[part 1 of 2: package /ComponentTypes]
AUTOSAR XML (schema 00046)
package /ComponentTypes
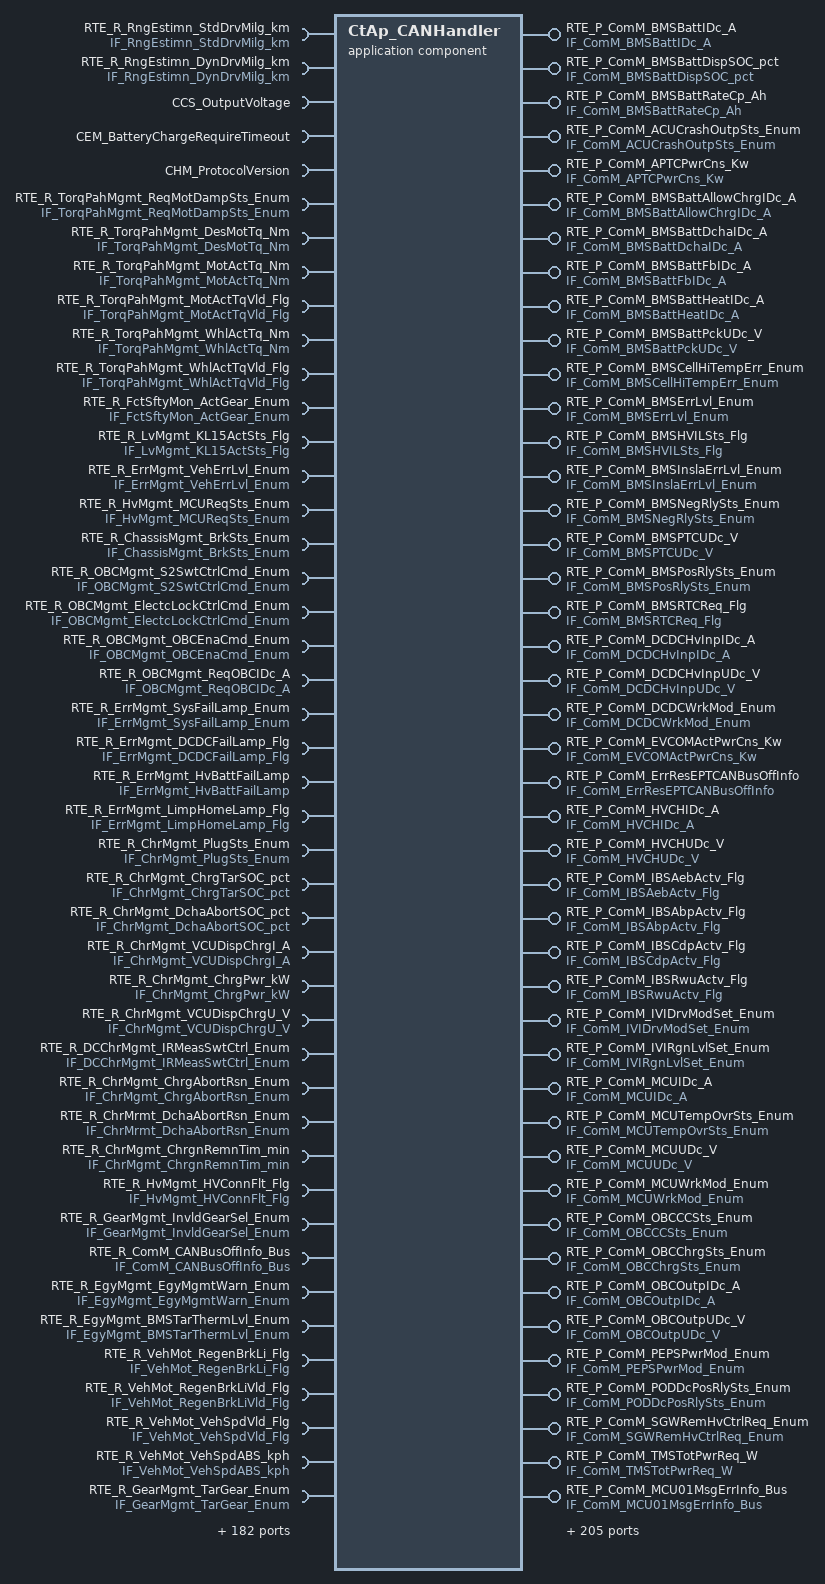
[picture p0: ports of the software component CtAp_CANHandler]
  application sw component type CtAp_CANHandler
    provide port RTE_P_ComM_BMSBattIDc_A: nonqueued-sender-com-spec{data-element=tec_ComM_BMSBattIDc_A, init-value=0}, provided-interface=IF_ComM_BMSBattIDc_A
    provide port RTE_P_ComM_BMSBattDispSOC_pct: nonqueued-sender-com-spec{data-element=tec_ComM_BMSBattDispSOC_pct, init-value=0}, provided-interface=IF_ComM_BMSBattDispSOC_pct
    provide port RTE_P_ComM_BMSBattRateCp_Ah: nonqueued-sender-com-spec{data-element=tec_ComM_BMSBattRateCp_Ah, init-value=0}, provided-interface=IF_ComM_BMSBattRateCp_Ah
    5 x require port:
      RTE_R_RngEstimn_StdDrvMilg_km: nonqueued-receiver-com-spec{data-element=tec_RngEstimn_StdDrvMilg_km, filter=data-filter-type=ALWAYS, init-value=0}, required-interface=IF_RngEstimn_StdDrvMilg_km
      RTE_R_RngEstimn_DynDrvMilg_km: nonqueued-receiver-com-spec{data-element=tec_RngEstimn_DynDrvMilg_km, filter=data-filter-type=ALWAYS, init-value=0}, required-interface=IF_RngEstimn_DynDrvMilg_km
      CCS_OutputVoltage: nonqueued-receiver-com-spec{data-element=CCS_OutputVoltage, init-value=0}, required-interface=CCS_OutputVoltage
      CEM_BatteryChargeRequireTimeout: nonqueued-receiver-com-spec{data-element=CEM_BatteryChargeRequireTimeout, init-value=0}, required-interface=CEM_BatteryChargeRequireTimeout
      CHM_ProtocolVersion: nonqueued-receiver-com-spec{data-element=CHM_ProtocolVersion, init-value=0}, required-interface=CHM_ProtocolVersion
    46 x provide port:
      RTE_P_ComM_ACUCrashOutpSts_Enum: nonqueued-sender-com-spec{data-element=tec_ComM_ACUCrashOutpSts_Enum, init-value=0}, provided-interface=IF_ComM_ACUCrashOutpSts_Enum
      RTE_P_ComM_APTCPwrCns_Kw: nonqueued-sender-com-spec{data-element=tec_ComM_APTCPwrCns_Kw, init-value=0}, provided-interface=IF_ComM_APTCPwrCns_Kw
      RTE_P_ComM_BMSBattAllowChrgIDc_A: nonqueued-sender-com-spec{data-element=tec_ComM_BMSBattAllowChrgIDc_A, init-value=0}, provided-interface=IF_ComM_BMSBattAllowChrgIDc_A
      RTE_P_ComM_BMSBattDchaIDc_A: nonqueued-sender-com-spec{data-element=tec_ComM_BMSBattDchaIDc_A, init-value=0}, provided-interface=IF_ComM_BMSBattDchaIDc_A
      RTE_P_ComM_BMSBattFbIDc_A: nonqueued-sender-com-spec{data-element=tec_ComM_BMSBattFbIDc_A, init-value=0}, provided-interface=IF_ComM_BMSBattFbIDc_A
      RTE_P_ComM_BMSBattHeatIDc_A: nonqueued-sender-com-spec{data-element=tec_ComM_BMSBattHeatIDc_A, init-value=0}, provided-interface=IF_ComM_BMSBattHeatIDc_A
      RTE_P_ComM_BMSBattPckUDc_V: nonqueued-sender-com-spec{data-element=tec_ComM_BMSBattPckUDc_V, init-value=0}, provided-interface=IF_ComM_BMSBattPckUDc_V
      RTE_P_ComM_BMSCellHiTempErr_Enum: nonqueued-sender-com-spec{data-element=tec_ComM_BMSCellHiTempErr_Enum, init-value=0}, provided-interface=IF_ComM_BMSCellHiTempErr_Enum
      RTE_P_ComM_BMSErrLvl_Enum: nonqueued-sender-com-spec{data-element=tec_ComM_BMSErrLvl_Enum, init-value=0}, provided-interface=IF_ComM_BMSErrLvl_Enum
      RTE_P_ComM_BMSHVILSts_Flg: nonqueued-sender-com-spec{data-element=tec_ComM_BMSHVILSts_Flg, init-value=0}, provided-interface=IF_ComM_BMSHVILSts_Flg
      RTE_P_ComM_BMSInslaErrLvl_Enum: nonqueued-sender-com-spec{data-element=tec_ComM_BMSInslaErrLvl_Enum, init-value=0}, provided-interface=IF_ComM_BMSInslaErrLvl_Enum
      RTE_P_ComM_BMSNegRlySts_Enum: nonqueued-sender-com-spec{data-element=tec_ComM_BMSNegRlySts_Enum, init-value=0}, provided-interface=IF_ComM_BMSNegRlySts_Enum
      RTE_P_ComM_BMSPTCUDc_V: nonqueued-sender-com-spec{data-element=tec_ComM_BMSPTCUDc_V, init-value=0}, provided-interface=IF_ComM_BMSPTCUDc_V
      RTE_P_ComM_BMSPosRlySts_Enum: nonqueued-sender-com-spec{data-element=tec_ComM_BMSPosRlySts_Enum, init-value=0}, provided-interface=IF_ComM_BMSPosRlySts_Enum
      RTE_P_ComM_BMSRTCReq_Flg: nonqueued-sender-com-spec{data-element=tec_ComM_BMSRTCReq_Flg, init-value=0}, provided-interface=IF_ComM_BMSRTCReq_Flg
      RTE_P_ComM_DCDCHvInpIDc_A: nonqueued-sender-com-spec{data-element=tec_ComM_DCDCHvInpIDc_A, init-value=0}, provided-interface=IF_ComM_DCDCHvInpIDc_A
      RTE_P_ComM_DCDCHvInpUDc_V: nonqueued-sender-com-spec{data-element=tec_ComM_DCDCHvInpUDc_V, init-value=0}, provided-interface=IF_ComM_DCDCHvInpUDc_V
      RTE_P_ComM_DCDCWrkMod_Enum: nonqueued-sender-com-spec{data-element=tec_ComM_DCDCWrkMod_Enum, init-value=0}, provided-interface=IF_ComM_DCDCWrkMod_Enum
      RTE_P_ComM_EVCOMActPwrCns_Kw: nonqueued-sender-com-spec{data-element=tec_ComM_EVCOMActPwrCns_Kw, init-value=0}, provided-interface=IF_ComM_EVCOMActPwrCns_Kw
      RTE_P_ComM_ErrResEPTCANBusOffInfo: nonqueued-sender-com-spec{data-element=tec_ComM_ErrResEPTCANBusOffInfo, init-value=0}, provided-interface=IF_ComM_ErrResEPTCANBusOffInfo
      RTE_P_ComM_HVCHIDc_A: nonqueued-sender-com-spec{data-element=tec_ComM_HVCHIDc_A, init-value=0}, provided-interface=IF_ComM_HVCHIDc_A
      RTE_P_ComM_HVCHUDc_V: nonqueued-sender-com-spec{data-element=tec_ComM_HVCHUDc_V, init-value=0}, provided-interface=IF_ComM_HVCHUDc_V
      RTE_P_ComM_IBSAebActv_Flg: nonqueued-sender-com-spec{data-element=tec_ComM_IBSAebActv_Flg, init-value=0}, provided-interface=IF_ComM_IBSAebActv_Flg
      RTE_P_ComM_IBSAbpActv_Flg: nonqueued-sender-com-spec{data-element=tec_ComM_IBSAbpActv_Flg, init-value=0}, provided-interface=IF_ComM_IBSAbpActv_Flg
      RTE_P_ComM_IBSCdpActv_Flg: nonqueued-sender-com-spec{data-element=tec_ComM_IBSCdpActv_Flg, init-value=0}, provided-interface=IF_ComM_IBSCdpActv_Flg
      RTE_P_ComM_IBSRwuActv_Flg: nonqueued-sender-com-spec{data-element=tec_ComM_IBSRwuActv_Flg, init-value=0}, provided-interface=IF_ComM_IBSRwuActv_Flg
      RTE_P_ComM_IVIDrvModSet_Enum: nonqueued-sender-com-spec{data-element=tec_ComM_IVIDrvModSet_Enum, init-value=0}, provided-interface=IF_ComM_IVIDrvModSet_Enum
      RTE_P_ComM_IVIRgnLvlSet_Enum: nonqueued-sender-com-spec{data-element=tec_ComM_IVIRgnLvlSet_Enum, init-value=0}, provided-interface=IF_ComM_IVIRgnLvlSet_Enum
      RTE_P_ComM_MCUIDc_A: nonqueued-sender-com-spec{data-element=tec_ComM_MCUIDc_A, init-value=0}, provided-interface=IF_ComM_MCUIDc_A
      RTE_P_ComM_MCUTempOvrSts_Enum: nonqueued-sender-com-spec{data-element=tec_ComM_MCUTempOvrSts_Enum, init-value=0}, provided-interface=IF_ComM_MCUTempOvrSts_Enum
      RTE_P_ComM_MCUUDc_V: nonqueued-sender-com-spec{data-element=tec_ComM_MCUUDc_V, init-value=0}, provided-interface=IF_ComM_MCUUDc_V
      RTE_P_ComM_MCUWrkMod_Enum: nonqueued-sender-com-spec{data-element=tec_ComM_MCUWrkMod_Enum, init-value=0}, provided-interface=IF_ComM_MCUWrkMod_Enum
      RTE_P_ComM_OBCCCSts_Enum: nonqueued-sender-com-spec{data-element=tec_ComM_OBCCCSts_Enum, init-value=0}, provided-interface=IF_ComM_OBCCCSts_Enum
      RTE_P_ComM_OBCChrgSts_Enum: nonqueued-sender-com-spec{data-element=tec_ComM_OBCChrgSts_Enum, init-value=0}, provided-interface=IF_ComM_OBCChrgSts_Enum
      RTE_P_ComM_OBCOutpIDc_A: nonqueued-sender-com-spec{data-element=tec_ComM_OBCOutpIDc_A, init-value=0}, provided-interface=IF_ComM_OBCOutpIDc_A
      RTE_P_ComM_OBCOutpUDc_V: nonqueued-sender-com-spec{data-element=tec_ComM_OBCOutpUDc_V, init-value=0}, provided-interface=IF_ComM_OBCOutpUDc_V
      RTE_P_ComM_PEPSPwrMod_Enum: nonqueued-sender-com-spec{data-element=tec_ComM_PEPSPwrMod_Enum, init-value=0}, provided-interface=IF_ComM_PEPSPwrMod_Enum
      RTE_P_ComM_PODDcPosRlySts_Enum: nonqueued-sender-com-spec{data-element=tec_ComM_PODDcPosRlySts_Enum, init-value=0}, provided-interface=IF_ComM_PODDcPosRlySts_Enum
      RTE_P_ComM_SGWRemHvCtrlReq_Enum: nonqueued-sender-com-spec{data-element=tec_ComM_SGWRemHvCtrlReq_Enum, init-value=0}, provided-interface=IF_ComM_SGWRemHvCtrlReq_Enum
      RTE_P_ComM_TMSTotPwrReq_W: nonqueued-sender-com-spec{data-element=tec_ComM_TMSTotPwrReq_W, init-value=0}, provided-interface=IF_ComM_TMSTotPwrReq_W
      RTE_P_ComM_MCU01MsgErrInfo_Bus: provided-interface=IF_ComM_MCU01MsgErrInfo_Bus
        provided-com-specs:
          data-element=tec_ComM_MCU01TimeoutInfo_Bus, init-value=fields=[ComM_MonStatMCU01TimeoutInfo:0, ComM_MonResMCU01TimeoutInfo:0, ComM_ErrStatMCU01TimeoutInfo:0, ComM_ErrResMCU01TimeoutInfo:0]
          data-element=tec_ComM_MCU01CRCDTCInfo_Bus, init-value=fields=[ComM_MonStatMCU01CRCDTCErrorInfo:0, ComM_MonResMCU01CRCDTCErrorInfo:0, ComM_ErrStatMCU01CRCDTCErrorInfo:0, ComM_ErrResMCU01CRCDTCErrorInfo:0]
          data-element=tec_ComM_MCU01CRCInfo_Bus, init-value=fields=[ComM_MonStatMCU01CRCErrorInfo:0, ComM_MonResMCU01CRCErrorInfo:0, ComM_ErrStatMCU01CRCErrorInfo:0, ComM_ErrResMCU01CRCErrorInfo:0]
          data-element=tec_ComM_MCU01TimeoutDTCInfo_Bus, init-value=fields=[ComM_MonStatMCU01TimeoutDTCErrorInfo:0, ComM_MonResMCU01TimeoutDTCErrorInfo:0, ComM_ErrStatMCU01TimeoutDTCErrorInfo:0, ComM_ErrResMCU01TimeoutDTCErrorInfo:0]
          data-element=tec_ComM_MCU01E2ETimeoutInfo_Bus, init-value=fields=[ComM_MonStatMCU01E2ETimeoutInfo:0, ComM_MonResMCU01E2ETimeoutInfo:0, ComM_ErrStatMCU01E2ETimeoutInfo:0, ComM_ErrResMCU01E2ETimeoutInfo:0]
      RTE_P_ComM_MotActSpd_rpm: nonqueued-sender-com-spec{data-element=tec_ComM_MotActSpd_rpm, init-value=0}, provided-interface=IF_ComM_MotActSpd_rpm
      RTE_P_ComM_MotMaxTq_Nm: nonqueued-sender-com-spec{data-element=tec_ComM_MotMaxTq_Nm, init-value=0}, provided-interface=IF_ComM_MotMaxTq_Nm
      RTE_P_ComM_MotMinTq_Nm: nonqueued-sender-com-spec{data-element=tec_ComM_MotMinTq_Nm, init-value=0}, provided-interface=IF_ComM_MotMinTq_Nm
      RTE_P_ComM_MotActTqVld_Flg: nonqueued-sender-com-spec{data-element=tec_ComM_MotActTqVld_Flg, init-value=0}, provided-interface=IF_ComM_MotActTqVld_Flg
      RTE_P_ComM_MotActTq_Nm: nonqueued-sender-com-spec{data-element=tec_ComM_MotActTq_Nm, init-value=0}, provided-interface=IF_ComM_MotActTq_Nm
    6 x require port:
      RTE_R_TorqPahMgmt_ReqMotDampSts_Enum: nonqueued-receiver-com-spec{data-element=tec_TorqPahMgmt_ReqMotDampSts_Enum, filter=data-filter-type=ALWAYS, init-value=0}, required-interface=IF_TorqPahMgmt_ReqMotDampSts_Enum
      RTE_R_TorqPahMgmt_DesMotTq_Nm: nonqueued-receiver-com-spec{data-element=tec_TorqPahMgmt_DesMotTq_Nm, filter=data-filter-type=ALWAYS, init-value=0}, required-interface=IF_TorqPahMgmt_DesMotTq_Nm
      RTE_R_TorqPahMgmt_MotActTq_Nm: nonqueued-receiver-com-spec{data-element=tec_TorqPahMgmt_MotActTq_Nm, filter=data-filter-type=ALWAYS, init-value=0}, required-interface=IF_TorqPahMgmt_MotActTq_Nm
      RTE_R_TorqPahMgmt_MotActTqVld_Flg: nonqueued-receiver-com-spec{data-element=tec_TorqPahMgmt_MotActTqVld_Flg, filter=data-filter-type=ALWAYS, init-value=0}, required-interface=IF_TorqPahMgmt_MotActTqVld_Flg
      RTE_R_TorqPahMgmt_WhlActTq_Nm: nonqueued-receiver-com-spec{data-element=tec_TorqPahMgmt_WhlActTq_Nm, filter=data-filter-type=ALWAYS, init-value=0}, required-interface=IF_TorqPahMgmt_WhlActTq_Nm
      RTE_R_TorqPahMgmt_WhlActTqVld_Flg: nonqueued-receiver-com-spec{data-element=tec_TorqPahMgmt_WhlActTqVld_Flg, filter=data-filter-type=ALWAYS, init-value=0}, required-interface=IF_TorqPahMgmt_WhlActTqVld_Flg
    provide port RTE_P_ComM_IBSVCUMotCtrlMsgErrInfo_Bus: provided-interface=IF_ComM_IBSVCUMotCtrlMsgErrInfo_Bus
      provided-com-specs:
        data-element=tec_ComM_IBSVCUMotCtrlCRCDTCInfo_Bus, init-value=fields=[ComM_MonStatIBSVCUMotCtrlCRCDTCErrorInfo:0, ComM_MonResIBSVCUMotCtrlCRCDTCErrorInfo:0, ComM_ErrStatIBSVCUMotCtrlCRCDTCErrorInfo:0, ComM_ErrResIBSVCUMotCtrlCRCDTCErrorInfo:0]
        data-element=tec_ComM_IBSVCUMotCtrlTimeoutInfo_Bus, init-value=fields=[ComM_MonStatIBSVCUMotCtrlTimeoutInfo:0, ComM_MonResIBSVCUMotCtrlTimeoutInfo:0, ComM_ErrStatIBSVCUMotCtrlTimeoutInfo:0, ComM_ErrResIBSVCUMotCtrlTimeoutInfo:0]
        data-element=tec_ComM_IBSVCUMotCtrlCRCInfo_Bus, init-value=fields=[ComM_MonStatIBSVCUMotCtrlCRCErrorInfo:0, ComM_MonResIBSVCUMotCtrlCRCErrorInfo:0, ComM_ErrStatIBSVCUMotCtrlCRCErrorInfo:0, ComM_ErrResIBSVCUMotCtrlCRCErrorInfo:0]
        data-element=tec_ComM_IBSVCUMotCtrlTimeoutDTCInfo_Bus, init-value=fields=[ComM_MonStatIBSVCUMotCtrlTimeoutDTCErrorInfo:0, ComM_MonResIBSVCUMotCtrlTimeoutDTCErrorInfo:0, ComM_ErrStatIBSVCUMotCtrlTimeoutDTCErrorInfo:0, ComM_ErrResIBSVCUMotCtrlTimeoutDTCErrorInfo:0]
        data-element=tec_ComM_IBSVCUMotCtrlE2ETimeoutInfo_Bus, init-value=fields=[ComM_MonStatIBSVCUMotCtrlE2ETimeoutInfo:0, ComM_MonResIBSVCUMotCtrlE2ETimeoutInfo:0, ComM_ErrStatIBSVCUMotCtrlE2ETimeoutInfo:0, ComM_ErrResIBSVCUMotCtrlE2ETimeoutInfo:0]
    require port RTE_R_FctSftyMon_ActGear_Enum: nonqueued-receiver-com-spec{data-element=tec_FctSftyMon_ActGear_Enum, filter=data-filter-type=ALWAYS, init-value=0}, required-interface=IF_FctSftyMon_ActGear_Enum
    provide port RTE_P_ComM_MotActSpdVld_Flg: nonqueued-sender-com-spec{data-element=tec_ComM_MotActSpdVld_Flg, init-value=0}, provided-interface=IF_ComM_MotActSpdVld_Flg
    require port RTE_R_LvMgmt_KL15ActSts_Flg: nonqueued-receiver-com-spec{data-element=tec_LvMgmt_KL15ActSts_Flg, filter=data-filter-type=ALWAYS, init-value=0}, required-interface=IF_LvMgmt_KL15ActSts_Flg
    require port RTE_R_ErrMgmt_VehErrLvl_Enum: nonqueued-receiver-com-spec{data-element=tec_ErrMgmt_VehErrLvl_Enum, filter=data-filter-type=ALWAYS, init-value=0}, required-interface=IF_ErrMgmt_VehErrLvl_Enum
    require port RTE_R_HvMgmt_MCUReqSts_Enum: nonqueued-receiver-com-spec{data-element=tec_HvMgmt_MCUReqSts_Enum, filter=data-filter-type=ALWAYS, init-value=0}, required-interface=IF_HvMgmt_MCUReqSts_Enum
    19 x provide port:
      RTE_P_ComM_BMSSts02MsgErrInfo_Bus: provided-interface=IF_ComM_BMSSts02MsgErrInfo_Bus
        provided-com-specs:
          data-element=tec_ComM_BMSSts02TimeoutDTCInfo_Bus, init-value=fields=[ComM_MonStatBMSSts02TimeoutDTCErrorInfo:0, ComM_MonResBMSSts02TimeoutDTCErrorInfo:0, ComM_ErrStatBMSSts02TimeoutDTCErrorInfo:0, ComM_ErrResBMSSts02TimeoutDTCErrorInfo:0]
          data-element=tec_ComM_BMSSts02TimeoutInfo_Bus, init-value=fields=[ComM_MonStatBMSSts02TimeoutInfo:0, ComM_MonResBMSSts02TimeoutInfo:0, ComM_ErrStatBMSSts02TimeoutInfo:0, ComM_ErrResBMSSts02TimeoutInfo:0]
      RTE_P_ComM_IBSSts02MsgErrInfo_Bus: provided-interface=IF_ComM_IBSSts02MsgErrInfo_Bus
        provided-com-specs:
          data-element=tec_ComM_IBSSts02CRCInfo_Bus, init-value=fields=[ComM_MonStatIBSSts02CRCErrorInfo:0, ComM_MonResIBSSts02CRCErrorInfo:0, ComM_ErrStatIBSSts02CRCErrorInfo:0, ComM_ErrResIBSSts02CRCErrorInfo:0]
          data-element=tec_ComM_IBSSts02CRCDTCInfo_Bus, init-value=fields=[ComM_MonStatIBSSts02CRCDTCErrorInfo:0, ComM_MonResIBSSts02CRCDTCErrorInfo:0, ComM_ErrStatIBSSts02CRCDTCErrorInfo:0, ComM_ErrResIBSSts02CRCDTCErrorInfo:0]
          data-element=tec_ComM_IBSSts02TimeoutDTCInfo_Bus, init-value=fields=[ComM_MonStatIBSSts02TimeoutDTCErrorInfo:0, ComM_MonResIBSSts02TimeoutDTCErrorInfo:0, ComM_ErrStatIBSSts02TimeoutDTCErrorInfo:0, ComM_ErrResIBSSts02TimeoutDTCErrorInfo:0]
          data-element=tec_ComM_IBSSts02E2ETimeoutInfo_Bus, init-value=fields=[ComM_MonStatIBSSts02E2ETimeoutInfo:0, ComM_MonResIBSSts02E2ETimeoutInfo:0, ComM_ErrStatIBSSts02E2ETimeoutInfo:0, ComM_ErrResIBSSts02E2ETimeoutInfo:0]
      RTE_P_ComM_IBSSts03MsgErrInfo_Bus: provided-interface=IF_ComM_IBSSts03MsgErrInfo_Bus
        provided-com-specs:
          data-element=tec_ComM_IBSSts03CRCInfo_Bus, init-value=fields=[ComM_MonStatIBSSts03CRCErrorInfo:0, ComM_MonResIBSSts03CRCErrorInfo:0, ComM_ErrStatIBSSts03CRCErrorInfo:0, ComM_ErrResIBSSts03CRCErrorInfo:0]
          data-element=tec_ComM_IBSSts03CRCDTCInfo_Bus, init-value=fields=[ComM_MonStatIBSSts03CRCDTCErrorInfo:0, ComM_MonResIBSSts03CRCDTCErrorInfo:0, ComM_ErrStatIBSSts03CRCDTCErrorInfo:0, ComM_ErrResIBSSts03CRCDTCErrorInfo:0]
          data-element=tec_ComM_IBSSts03TimeoutDTCInfo_Bus, init-value=fields=[ComM_MonStatIBSSts03TimeoutDTCErrorInfo:0, ComM_MonResIBSSts03TimeoutDTCErrorInfo:0, ComM_ErrStatIBSSts03TimeoutDTCErrorInfo:0, ComM_ErrResIBSSts03TimeoutDTCErrorInfo:0]
          data-element=tec_ComM_IBSSts03E2ETimeoutInfo_Bus, init-value=fields=[ComM_MonStatIBSSts03E2ETimeoutInfo:0, ComM_MonResIBSSts03E2ETimeoutInfo:0, ComM_ErrStatIBSSts03E2ETimeoutInfo:0, ComM_ErrResIBSSts03E2ETimeoutInfo:0]
      RTE_P_ComM_IBSSts05MsgErrInfo_Bus: provided-interface=IF_ComM_IBSSts05MsgErrInfo_Bus
        provided-com-specs:
          data-element=tec_ComM_IBSSts05CRCDTCInfo_Bus, init-value=fields=[ComM_MonStatIBSSts05CRCDTCErrorInfo:0, ComM_MonResIBSSts05CRCDTCErrorInfo:0, ComM_ErrStatIBSSts05CRCDTCErrorInfo:0, ComM_ErrResIBSSts05CRCDTCErrorInfo:0]
          data-element=tec_ComM_IBSSts05TimeoutDTCInfo_Bus, init-value=fields=[ComM_MonStatIBSSts05TimeoutDTCErrorInfo:0, ComM_MonResIBSSts05TimeoutDTCErrorInfo:0, ComM_ErrStatIBSSts05TimeoutDTCErrorInfo:0, ComM_ErrResIBSSts05TimeoutDTCErrorInfo:0]
          data-element=tec_ComM_IBSSts05TimeoutInfo_Bus, init-value=fields=[ComM_MonStatIBSSts05TimeoutInfo:0, ComM_MonResIBSSts05TimeoutInfo:0, ComM_ErrStatIBSSts05TimeoutInfo:0, ComM_ErrResIBSSts05TimeoutInfo:0]
          tec_ComM_IBSSts05CRCInfo_Bus
          tec_ComM_IBSSts05E2ETimeoutInfo_Bus
      RTE_P_ComM_IBSSts06MsgErrInfo_Bus: provided-interface=IF_ComM_IBSSts06MsgErrInfo_Bus
        provided-com-specs:
          data-element=tec_ComM_IBSSts06CRCDTCInfo_Bus, init-value=fields=[ComM_MonStatIBSSts06CRCDTCErrorInfo:0, ComM_MonResIBSSts06CRCDTCErrorInfo:0, ComM_ErrStatIBSSts06CRCDTCErrorInfo:0, ComM_ErrResIBSSts06CRCDTCErrorInfo:0]
          data-element=tec_ComM_IBSSts06TimeoutDTCInfo_Bus, init-value=fields=[ComM_MonStatIBSSts06TimeoutDTCErrorInfo:0, ComM_MonResIBSSts06TimeoutDTCErrorInfo:0, ComM_ErrStatIBSSts06TimeoutDTCErrorInfo:0, ComM_ErrResIBSSts06TimeoutDTCErrorInfo:0]
      RTE_P_ComM_IBSTqMsgErrInfo_Bus: provided-interface=IF_ComM_IBSTqMsgErrInfo_Bus
        provided-com-specs:
          data-element=tec_ComM_IBSTqCRCDTCInfo_Bus, init-value=fields=[ComM_MonStatIBSTqCRCDTCErrorInfo:0, ComM_MonResIBSTqCRCDTCErrorInfo:0, ComM_ErrStatIBSTqCRCDTCErrorInfo:0, ComM_ErrResIBSTqCRCDTCErrorInfo:0]
          data-element=tec_ComM_IBSTqTimeoutDTCInfo_Bus, init-value=fields=[ComM_MonStatIBSTqTimeoutDTCErrorInfo:0, ComM_MonResIBSTqTimeoutDTCErrorInfo:0, ComM_ErrStatIBSTqTimeoutDTCErrorInfo:0, ComM_ErrResIBSTqTimeoutDTCErrorInfo:0]
          data-element=tec_ComM_IBSTqCRCInfo_Bus, init-value=fields=[ComM_MonStatIBSTqCRCErrorInfo:0, ComM_MonResIBSTqCRCErrorInfo:0, ComM_ErrStatIBSTqCRCErrorInfo:0, ComM_ErrResIBSTqCRCErrorInfo:0]
          data-element=tec_ComM_IBSTqE2ETimeoutInfo_Bus, init-value=fields=[ComM_MonStatIBSTqE2ETimeoutInfo:0, ComM_MonResIBSTqE2ETimeoutInfo:0, ComM_ErrStatIBSTqE2ETimeoutInfo:0, ComM_ErrResIBSTqE2ETimeoutInfo:0]
      RTE_P_ComM_IBSWhlSpd01MsgErrInfo_Bus: provided-interface=IF_ComM_IBSWhlSpd01MsgErrInfo_Bus
        provided-com-specs:
          data-element=tec_ComM_IBSWhlSpd01CRCDTCInfo_Bus, init-value=fields=[ComM_MonStatIBSWhlSpd01CRCDTCErrorInfo:0, ComM_MonResIBSWhlSpd01CRCDTCErrorInfo:0, ComM_ErrStatIBSWhlSpd01CRCDTCErrorInfo:0, ComM_ErrResIBSWhlSpd01CRCDTCErrorInfo:0]
          data-element=tec_ComM_IBSWhlSpd01TimeoutDTCInfo_Bus, init-value=fields=[ComM_MonStatIBSWhlSpd01TimeoutInfo:0, ComM_MonResIBSWhlSpd01TimeoutInfo:0, ComM_ErrStatIBSWhlSpd01TimeoutInfo:0, ComM_ErrResIBSWhlSpd01TimeoutInfo:0]
      RTE_P_ComM_IBSWhlSpd02MsgErrInfo_Bus: provided-interface=IF_ComM_IBSWhlSpd02MsgErrInfo_Bus
        provided-com-specs:
          data-element=tec_ComM_IBSWhlSpd02CRCDTCInfo_Bus, init-value=fields=[ComM_MonStatIBSWhlSpd02CRCDTCErrorInfo:0, ComM_MonResIBSWhlSpd02CRCDTCErrorInfo:0, ComM_ErrStatIBSWhlSpd02CRCDTCErrorInfo:0, ComM_ErrResIBSWhlSpd02CRCDTCErrorInfo:0]
          data-element=tec_ComM_IBSWhlSpd02TimeoutDTCInfo_Bus, init-value=fields=[ComM_MonStatIBSWhlSpd02TimeoutInfo:0, ComM_MonResIBSWhlSpd02TimeoutInfo:0, ComM_ErrStatIBSWhlSpd02TimeoutInfo:0, ComM_ErrResIBSWhlSpd02TimeoutInfo:0]
      RTE_P_ComM_IBSACCMsgErrInfo_Bus: provided-interface=IF_ComM_IBSACCMsgErrInfo_Bus
        provided-com-specs:
          data-element=tec_ComM_IBSACCCRCDTCInfo_Bus, init-value=fields=[ComM_MonStatIBSACCCRCDTCErrorInfo:0, ComM_MonResIBSACCCRCDTCErrorInfo:0, ComM_ErrStatIBSACCCRCDTCErrorInfo:0, ComM_ErrResIBSACCCRCDTCErrorInfo:0]
          data-element=tec_ComM_IBSACCCRCInfo_Bus, init-value=fields=[ComM_MonStatIBSACCCRCErrorInfo:0, ComM_MonResIBSACCCRCErrorInfo:0, ComM_ErrStatIBSACCCRCErrorInfo:0, ComM_ErrResIBSACCCRCErrorInfo:0]
          data-element=tec_ComM_IBSACCTimeoutDTCInfo_Bus, init-value=fields=[ComM_MonStatIBSACCTimeoutDTCErrorInfo:0, ComM_MonResIBSACCTimeoutDTCErrorInfo:0, ComM_ErrStatIBSACCTimeoutDTCErrorInfo:0, ComM_ErrResIBSACCTimeoutDTCErrorInfo:0]
          data-element=tec_ComM_IBSACCE2ETimeoutInfo_Bus, init-value=fields=[ComM_MonStatIBSACCE2ETimeoutInfo:0, ComM_MonResIBSACCE2ETimeoutInfo:0, ComM_ErrStatIBSACCE2ETimeoutInfo:0, ComM_ErrResIBSACCE2ETimeoutInfo:0]
      RTE_P_ComM_IVI01MsgErrInfo_Bus: provided-interface=IF_ComM_IVI01MsgErrInfo_Bus
        provided-com-specs:
          data-element=tec_ComM_IVI01CRCInfo_Bus, init-value=fields=[ComM_MonStatIVI01CRCErrorInfo:0, ComM_MonResIVI01CRCErrorInfo:0, ComM_ErrStatIVI01CRCErrorInfo:0, ComM_ErrResIVI01CRCErrorInfo:0]
          data-element=tec_ComM_IVI01E2ETimeoutInfo_Bus, init-value=fields=[ComM_MonStatIVI01E2ETimeoutInfo:0, ComM_MonResIVI01E2ETimeoutInfo:0, ComM_ErrStatIVI01E2ETimeoutInfo:0, ComM_ErrResIVI01E2ETimeoutInfo:0]
      RTE_P_ComM_PRNDMsgErrInfo_Bus: provided-interface=IF_ComM_PRNDMsgErrInfo_Bus
        provided-com-specs:
          data-element=tec_ComM_PRNDTimeoutInfo_Bus, init-value=fields=[ComM_MonStatPRNDTimeoutInfo:0, ComM_MonResPRNDTimeoutInfo:0, ComM_ErrStatPRNDTimeoutInfo:0, ComM_ErrResPRNDTimeoutInfo:0]
          data-element=tec_ComM_PRNDCRCDTCInfo_Bus, init-value=fields=[ComM_MonStatPRNDCRCDTCErrorInfo:0, ComM_MonResPRNDCRCDTCErrorInfo:0, ComM_ErrStatPRNDCRCDTCErrorInfo:0, ComM_ErrResPRNDCRCDTCErrorInfo:0]
          data-element=tec_ComM_PRNDCRCInfo_Bus, init-value=fields=[ComM_MonStatPRNDCRCErrorInfo:0, ComM_MonResPRNDCRCErrorInfo:0, ComM_ErrStatPRNDCRCErrorInfo:0, ComM_ErrResPRNDCRCErrorInfo:0]
          data-element=tec_ComM_PRNDTimeoutDTCInfo_Bus, init-value=fields=[ComM_MonStatPRNDTimeoutDTCErrorInfo:0, ComM_MonResPRNDTimeoutDTCErrorInfo:0, ComM_ErrStatPRNDTimeoutDTCErrorInfo:0, ComM_ErrResPRNDTimeoutDTCErrorInfo:0]
          data-element=tec_ComM_PRNDE2ETimeoutInfo_Bus, init-value=fields=[ComM_MonStatPRNDE2ETimeoutInfo:0, ComM_MonResPRNDE2ETimeoutInfo:0, ComM_ErrStatPRNDE2ETimeoutInfo:0, ComM_ErrResPRNDE2ETimeoutInfo:0]
      RTE_P_ComM_ACU01MsgErrInfo_Bus: provided-interface=IF_ComM_ACU01MsgErrInfo_Bus
        provided-com-specs:
          data-element=tec_ComM_ACU01CRCDTCInfo_Bus, init-value=fields=[ComM_MonStatACU01CRCDTCErrorInfo:0, ComM_MonResACU01CRCDTCErrorInfo:0, ComM_ErrStatACU01CRCDTCErrorInfo:0, ComM_ErrResACU01CRCDTCErrorInfo:0]
          data-element=tec_ComM_ACU01TimeoutDTCInfo_Bus, init-value=fields=[ComM_MonStatACU01TimeoutDTCInfo:0, ComM_MonResACU01TimeoutDTCInfo:0, ComM_ErrStatACU01TimeoutDTCInfo:0, ComM_ErrResACU01TimeoutDTCInfo:0]
      RTE_P_ComM_ACU02MsgErrInfo_Bus: provided-interface=IF_ComM_ACU02MsgErrInfo_Bus
        provided-com-specs:
          data-element=tec_ComM_ACU02CRCDTCInfo_Bus, init-value=fields=[ComM_MonStatACU02CRCDTCErrorInfo:0, ComM_MonResACU02CRCDTCErrorInfo:0, ComM_ErrStatACU02CRCDTCErrorInfo:0, ComM_ErrResACU02CRCDTCErrorInfo:0]
          data-element=tec_ComM_ACU02TimeoutDTCInfo_Bus, init-value=fields=[ComM_MonStatACU02TimeoutDTCInfo:0, ComM_MonResACU02TimeoutDTCInfo:0, ComM_ErrStatACU02TimeoutDTCInfo:0, ComM_ErrResACU02TimeoutDTCInfo:0]
          tec_ComM_ACU02TimeoutInfo_Bus
      RTE_P_ComM_ACUInfoMsgErrInfo_Bus: provided-interface=IF_ComM_ACUInfoMsgErrInfo_Bus
        provided-com-specs:
          data-element=tec_ComM_ACUInfoTimeoutDTCInfo_Bus, init-value=fields=[ComM_MonStatACUInfoTimeoutDTCErrorInfo:0, ComM_MonResACUInfoTimeoutDTCErrorInfo:0, ComM_ErrStatACUInfoTimeoutDTCErrorInfo:0, ComM_ErrResACUInfoTimeoutDTCErrorInfo:0]
          data-element=tec_ComM_ACUInfoTimeoutInfo_Bus, init-value=fields=[ComM_MonStatACUInfoTimeoutInfo:0, ComM_MonResACUInfoTimeoutInfo:0, ComM_ErrStatACUInfoTimeoutInfo:0, ComM_ErrResACUInfoTimeoutInfo:0]
          tec_ComM_ACUInfoCRCDTCInfo_Bus
      RTE_P_ComM_ADCUACC02MsgErrInfo_Bus: provided-interface=IF_ComM_ADCUACC02MsgErrInfo_Bus
        provided-com-specs:
          data-element=tec_ComM_ADCUACC02CRCDTCInfo_Bus, init-value=fields=[ComM_MonStatADCUACC02CRCDTCErrorInfo:0, ComM_MonResADCUACC02CRCDTCErrorInfo:0, ComM_ErrStatADCUACC02CRCDTCErrorInfo:0, ComM_ErrResADCUACC02CRCDTCErrorInfo:0]
          data-element=tec_ComM_ADCUACC02TimeoutDTCInfo_Bus, init-value=fields=[ComM_MonStatADCUACC02TimeoutDTCErrorInfo:0, ComM_MonResADCUACC02TimeoutDTCErrorInfo:0, ComM_ErrStatADCUACC02TimeoutDTCErrorInfo:0, ComM_ErrResADCUACC02TimeoutDTCErrorInfo:0]
          data-element=tec_ComM_ADCUACC02TimeoutInfo_Bus, init-value=fields=[ComM_MonStatADCUACC02TimeoutInfo:0, ComM_MonResADCUACC02TimeoutInfo:0, ComM_ErrStatADCUACC02TimeoutInfo:0, ComM_ErrResADCUACC02TimeoutInfo:0]
      RTE_P_ComM_IBSReqIncTqSts_Flg: nonqueued-sender-com-spec{data-element=tec_ComM_IBSReqIncTqSts_Flg, init-value=0}, provided-interface=IF_ComM_IBSReqIncTqSts_Flg
      RTE_P_ComM_IBSReqRednTqSts_Flg: nonqueued-sender-com-spec{data-element=tec_ComM_IBSReqRednTqSts_Flg, init-value=0}, provided-interface=IF_ComM_IBSReqRednTqSts_Flg
      RTE_P_ComM_IBSReqIncTq_Nm: nonqueued-sender-com-spec{data-element=tec_ComM_IBSReqIncTq_Nm, init-value=0}, provided-interface=IF_ComM_IBSReqIncTq_Nm
      RTE_P_ComM_IBSReqRednTq_Nm: nonqueued-sender-com-spec{data-element=tec_ComM_IBSReqRednTq_Nm, init-value=0}, provided-interface=IF_ComM_IBSReqRednTq_Nm
    require port RTE_R_ChassisMgmt_BrkSts_Enum: nonqueued-receiver-com-spec{data-element=tec_ChassisMgmt_BrkSts_Enum, filter=data-filter-type=ALWAYS, init-value=0}, required-interface=IF_ChassisMgmt_BrkSts_Enum
    provide port RTE_P_ComM_IBSDtcActv_Flg: nonqueued-sender-com-spec{data-element=tec_ComM_IBSDtcActv_Flg, init-value=0}, provided-interface=IF_ComM_IBSDtcActv_Flg
    provide port RTE_P_ComM_IBSSts04MsgErrInfo_Bus: provided-interface=IF_ComM_IBSSts04MsgErrInfo_Bus
      provided-com-specs:
        data-element=tec_ComM_IBSSts04CRCDTCInfo_Bus, init-value=fields=[ComM_MonStatIBSSts04CRCDTCErrorInfo:0, ComM_MonResIBSSts04CRCDTCErrorInfo:0, ComM_ErrStatIBSSts04CRCDTCErrorInfo:0, ComM_ErrResIBSSts04CRCDTCErrorInfo:0]
        data-element=tec_ComM_IBSSts04CRCInfo_Bus, init-value=fields=[ComM_MonStatIBSSts04CRCErrorInfo:0, ComM_MonResIBSSts04CRCErrorInfo:0, ComM_ErrStatIBSSts04CRCErrorInfo:0, ComM_ErrResIBSSts04CRCErrorInfo:0]
        data-element=tec_ComM_IBSSts04TimeoutDTCInfo_Bus, init-value=fields=[ComM_MonStatIBSSts04TimeoutDTCErrorInfo:0, ComM_MonResIBSSts04TimeoutDTCErrorInfo:0, ComM_ErrStatIBSSts04TimeoutDTCErrorInfo:0, ComM_ErrResIBSSts04TimeoutDTCErrorInfo:0]
        data-element=tec_ComM_IBSSts04E2ETimeoutInfo_Bus, init-value=fields=[ComM_MonStatIBSSts04E2ETimeoutInfo:0, ComM_MonResIBSSts04E2ETimeoutInfo:0, ComM_ErrStatIBSSts04E2ETimeoutInfo:0, ComM_ErrResIBSSts04E2ETimeoutInfo:0]
    4 x require port:
      RTE_R_OBCMgmt_S2SwtCtrlCmd_Enum: nonqueued-receiver-com-spec{data-element=tec_OBCMgmt_S2SwtCtrlCmd_Enum, filter=data-filter-type=ALWAYS, init-value=0}, required-interface=IF_OBCMgmt_S2SwtCtrlCmd_Enum
      RTE_R_OBCMgmt_ElectcLockCtrlCmd_Enum: nonqueued-receiver-com-spec{data-element=tec_OBCMgmt_ElectcLockCtrlCmd_Enum, filter=data-filter-type=ALWAYS, init-value=0}, required-interface=IF_OBCMgmt_ElectcLockCtrlCmd_Enum
      RTE_R_OBCMgmt_OBCEnaCmd_Enum: nonqueued-receiver-com-spec{data-element=tec_OBCMgmt_OBCEnaCmd_Enum, filter=data-filter-type=ALWAYS, init-value=0}, required-interface=IF_OBCMgmt_OBCEnaCmd_Enum
      RTE_R_OBCMgmt_ReqOBCIDc_A: nonqueued-receiver-com-spec{data-element=tec_OBCMgmt_ReqOBCIDc_A, filter=data-filter-type=ALWAYS, init-value=0}, required-interface=IF_OBCMgmt_ReqOBCIDc_A
    13 x provide port:
      RTE_P_ComM_BMSErrInfoTimeoutInfo_Bus: nonqueued-sender-com-spec{data-element=tec_ComM_BMSErrInfoTimeoutInfo_Bus, init-value=fields=[ComM_MonStatBMSErrInfoTimeoutInfo:0, ComM_MonResBMSErrInfoTimeoutInfo:0, ComM_ErrStatBMSErrInfoTimeoutInfo:0, ComM_ErrResBMSErrInfoTimeoutInfo:0]}, provided-interface=IF_ComM_BMSErrInfoTimeoutInfo_Bus
      RTE_P_ComM_PODSts01TimeoutInfo_Bus: nonqueued-sender-com-spec{data-element=tec_ComM_PODSts01TimeoutInfo_Bus, init-value=fields=[ComM_MonStatPODSts01TimeoutInfo:0, ComM_MonResPODSts01TimeoutInfo:0, ComM_ErrStatPODSts01TimeoutInfo:0, ComM_ErrResPODSts01TimeoutInfo:0]}, provided-interface=IF_ComM_PODSts01TimeoutInfo_Bus
      RTE_P_ComM_MinCellUDcErrSts_Enum: nonqueued-sender-com-spec{data-element=tec_ComM_MinCellUDcErrSts_Enum, init-value=0}, provided-interface=IF_ComM_MinCellUDcErrSts_Enum
      RTE_P_ComM_MaxCellUDcErrSts_Enum: nonqueued-sender-com-spec{data-element=tec_ComM_MaxCellUDcErrSts_Enum, init-value=0}, provided-interface=IF_ComM_MaxCellUDcErrSts_Enum
      RTE_P_ComM_ChrgnIDcErrSts_Enum: nonqueued-sender-com-spec{data-element=tec_ComM_ChrgnIDcErrSts_Enum, init-value=0}, provided-interface=IF_ComM_ChrgnIDcErrSts_Enum
      RTE_P_ComM_BMSSOCErrHiSts_Enum: nonqueued-sender-com-spec{data-element=tec_ComM_BMSSOCHiErrSts_Enum, init-value=0}, provided-interface=IF_ComM_BMSSOCErrHiSts_Enum
      RTE_P_ComM_BMSSOCErrLoSts_Enum: nonqueued-sender-com-spec{data-element=tec_ComM_BMSSOCLoErrSts_Enum, init-value=0}, provided-interface=IF_ComM_BMSSOCErrLoSts_Enum
      RTE_P_ComM_BMSErrRlySts_Enum: nonqueued-sender-com-spec{data-element=tec_ComM_BMSErrRlySts_Enum, init-value=0}, provided-interface=IF_ComM_BMSErrRlySts_Enum
      RTE_P_ComM_BCMAntithftSts_Enum: nonqueued-sender-com-spec{data-element=tec_ComM_BCMAntithftSts_Enum, init-value=0}, provided-interface=IF_ComM_BCMAntithftSts_Enum
      RTE_P_ComM_OBCErrLvl_Enum: nonqueued-sender-com-spec{data-element=tec_ComM_OBCErrLvl_Enum, init-value=0}, provided-interface=IF_ComM_OBCErrLvl_Enum
      RTE_P_ComM_DCDCErrLvl_Enum: nonqueued-sender-com-spec{data-element=tec_ComM_DCDCErrLvl_Enum, init-value=0}, provided-interface=IF_ComM_DCDCErrLvl_Enum
      RTE_P_ComM_BMSKeepWrmSts_Enum: nonqueued-sender-com-spec{data-element=tec_ComM_BMSKeepWrmSts_Enum, init-value=0}, provided-interface=IF_ComM_BMSKeepWrmSts_Enum
      RTE_P_ComM_BMSKeepWrmReq_Enum: nonqueued-sender-com-spec{data-element=tec_ComM_BMSKeepWrmReq_Enum, init-value=0}, provided-interface=IF_ComM_BMSKeepWrmReq_Enum
    19 x require port:
      RTE_R_ErrMgmt_SysFailLamp_Enum: nonqueued-receiver-com-spec{data-element=tec_ErrMgmt_SysFailLamp_Enum, filter=data-filter-type=ALWAYS, init-value=0}, required-interface=IF_ErrMgmt_SysFailLamp_Enum
      RTE_R_ErrMgmt_DCDCFailLamp_Flg: nonqueued-receiver-com-spec{data-element=tec_ErrMgmt_DCDCFailLamp_Flg, filter=data-filter-type=ALWAYS, init-value=0}, required-interface=IF_ErrMgmt_DCDCFailLamp_Flg
      RTE_R_ErrMgmt_HvBattFailLamp: nonqueued-receiver-com-spec{data-element=tec_ErrMgmt_HvBattFailLamp, filter=data-filter-type=ALWAYS, init-value=0}, required-interface=IF_ErrMgmt_HvBattFailLamp
      RTE_R_ErrMgmt_LimpHomeLamp_Flg: nonqueued-receiver-com-spec{data-element=tec_ErrMgmt_LimpHomeLamp_Flg, filter=data-filter-type=ALWAYS, init-value=0}, required-interface=IF_ErrMgmt_LimpHomeLamp_Flg
      RTE_R_ChrMgmt_PlugSts_Enum: nonqueued-receiver-com-spec{data-element=tec_ChrMgmt_PlugSts_Enum, filter=data-filter-type=ALWAYS, init-value=0}, required-interface=IF_ChrMgmt_PlugSts_Enum
      RTE_R_ChrMgmt_ChrgTarSOC_pct: nonqueued-receiver-com-spec{data-element=tec_ChrMgmt_ChrgTarSOC_pct, filter=data-filter-type=ALWAYS, init-value=0}, required-interface=IF_ChrMgmt_ChrgTarSOC_pct
      RTE_R_ChrMgmt_DchaAbortSOC_pct: nonqueued-receiver-com-spec{data-element=tec_ChrMgmt_DchaAbortSOC_pct, filter=data-filter-type=ALWAYS, init-value=0}, required-interface=IF_ChrMgmt_DchaAbortSOC_pct
      RTE_R_ChrMgmt_VCUDispChrgI_A: nonqueued-receiver-com-spec{data-element=tec_ChrMgmt_VCUDispChrgI_A, filter=data-filter-type=ALWAYS, init-value=0}, required-interface=IF_ChrMgmt_VCUDispChrgI_A
      RTE_R_ChrMgmt_ChrgPwr_kW: nonqueued-receiver-com-spec{data-element=tec_ChrMgmt_VCUDispChrgPwr_kW, filter=data-filter-type=ALWAYS, init-value=0}, required-interface=IF_ChrMgmt_ChrgPwr_kW
      RTE_R_ChrMgmt_VCUDispChrgU_V: nonqueued-receiver-com-spec{data-element=tec_ChrMgmt_VCUDispChrgU_V, filter=data-filter-type=ALWAYS, init-value=0}, required-interface=IF_ChrMgmt_VCUDispChrgU_V
      RTE_R_DCChrMgmt_IRMeasSwtCtrl_Enum: nonqueued-receiver-com-spec{data-element=tec_DCChrMgmt_IRMeasSwtCtrl_Enum, filter=data-filter-type=ALWAYS, init-value=0}, required-interface=IF_DCChrMgmt_IRMeasSwtCtrl_Enum
      RTE_R_ChrMgmt_ChrgAbortRsn_Enum: nonqueued-receiver-com-spec{data-element=tec_ChrMgmt_ChrgAbortRsn_Enum, filter=data-filter-type=ALWAYS, init-value=0}, required-interface=IF_ChrMgmt_ChrgAbortRsn_Enum
      RTE_R_ChrMrmt_DchaAbortRsn_Enum: nonqueued-receiver-com-spec{data-element=tec_ChrMgmt_DchaAbortRsn_Enum, filter=data-filter-type=ALWAYS, init-value=0}, required-interface=IF_ChrMrmt_DchaAbortRsn_Enum
      RTE_R_ChrMgmt_ChrgnRemnTim_min: nonqueued-receiver-com-spec{data-element=tec_ChrgMgmt_ChrgnRemnTim_min, filter=data-filter-type=ALWAYS, init-value=0}, required-interface=IF_ChrMgmt_ChrgnRemnTim_min
      RTE_R_HvMgmt_HVConnFlt_Flg: nonqueued-receiver-com-spec{data-element=tec_HvMgmt_HVConnFlt_Flg, filter=data-filter-type=ALWAYS, init-value=0}, required-interface=IF_HvMgmt_HVConnFlt_Flg
      RTE_R_GearMgmt_InvldGearSel_Enum: nonqueued-receiver-com-spec{data-element=tec_GearMgmt_InvldGearSel_Enum, filter=data-filter-type=ALWAYS, init-value=0}, required-interface=IF_GearMgmt_InvldGearSel_Enum
      RTE_R_ComM_CANBusOffInfo_Bus: required-interface=IF_ComM_CANBusOffInfo_Bus
        required-com-specs:
          data-element=tec_ComM_EPTCANBusOffInfo_Bus, filter=data-filter-type=ALWAYS, init-value=fields=[ComM_MonStatEPTCANBusOffInfo:0, ComM_MonResEPTCANBusOffInfo:0, ComM_ErrStatEPTCANBusOffInfo:0, ComM_ErrResEPTCANBusOffInfo:0]
          data-element=tec_ComM_CHCANBusOffInfo_Bus, filter=data-filter-type=ALWAYS, init-value=fields=[ComM_MonStatCHCANBusOffInfo:0, ComM_MonResCHCANBusOffInfo:0, ComM_ErrStatCHCANBusOffInfo:0, ComM_ErrResCHCANBusOffInfo:0]
          data-element=tec_ComM_EPTCANBusOffDTCInfo_Bus, filter=data-filter-type=ALWAYS, init-value=fields=[ComM_MonStatEPTCANBusOffDTCInfo:0, ComM_MonResEPTCANBusOffDTCInfo:0, ComM_ErrStatEPTCANBusOffDTCInfo:0, ComM_ErrResEPTCANBusOffDTCInfo:0]
          data-element=tec_ComM_CHCANBusOffDTCInfo_Bus, filter=data-filter-type=ALWAYS, init-value=fields=[ComM_MonStatCHCANBusOffDTCInfo:0, ComM_MonResCHCANBusOffDTCInfo:0, ComM_ErrStatCHCANBusOffDTCInfo:0, ComM_ErrResCHCANBusOffDTCInfo:0]
          data-element=tec_ComM_DCCANBusOffDTCInfo_Bus, filter=data-filter-type=ALWAYS, init-value=fields=[ComM_MonStatDCCANDTCBusOffInfo:0, ComM_MonResDCCANDTCBusOffInfo:0, ComM_ErrStatDCCANDTCBusOffInfo:0, ComM_ErrResDCCANDTCBusOffInfo:0]
          data-element=tec_ComM_DCCANBusOffInfo_Bus, filter=data-filter-type=ALWAYS, init-value=fields=[ComM_MonStatDCCANBusOffInfo:0, ComM_MonResDCCANBusOffInfo:0, ComM_ErrStatDCCANBusOffInfo:0, ComM_ErrResDCCANBusOffInfo:0]
      RTE_R_EgyMgmt_EgyMgmtWarn_Enum: nonqueued-receiver-com-spec{data-element=tec_EgyMgmt_EgyMgmtWarn_Enum, filter=data-filter-type=ALWAYS, init-value=0}, required-interface=IF_EgyMgmt_EgyMgmtWarn_Enum
      RTE_R_EgyMgmt_BMSTarThermLvl_Enum: nonqueued-receiver-com-spec{data-element=tec_EgyMgmt_BMSTarThermLvl_Enum, filter=data-filter-type=ALWAYS, init-value=0}, required-interface=IF_EgyMgmt_BMSTarThermLvl_Enum
    31 x provide port:
      RTE_P_ComM_IBSTcsActv_Flg: nonqueued-sender-com-spec{data-element=tec_ComM_IBSTcsActv_Flg, init-value=0}, provided-interface=IF_ComM_IBSTcsActv_Flg
      RTE_P_ComM_IBSVdcActv_Flg: nonqueued-sender-com-spec{data-element=tec_ComM_IBSVdcActv_Flg, init-value=0}, provided-interface=IF_ComM_IBSVdcActv_Flg
      RTE_P_ComM_IBSHdcSts_Enum: nonqueued-sender-com-spec{data-element=tec_ComM_IBSHdcSts_Enum, init-value=0}, provided-interface=IF_ComM_IBSHdcSts_Enum
      RTE_P_ComM_IBSSts01MsgErrInfo_Bus: provided-interface=IF_ComM_IBSSts01MsgErrInfo_Bus
        provided-com-specs:
          data-element=tec_ComM_IBSSts01CRCDTCInfo_Bus, init-value=fields=[ComM_MonStatIBSSts01CRCDTCErrorInfo:0, ComM_MonResIBSSts01CRCDTCErrorInfo:0, ComM_ErrStatIBSSts01CRCDTCErrorInfo:0, ComM_ErrResIBSSts01CRCDTCErrorInfo:0]
          data-element=tec_ComM_IBSSts01TimeoutDTCInfo_Bus, init-value=fields=[ComM_MonStatIBSSts01TimeoutDTCErrorInfo:0, ComM_MonResIBSSts01TimeoutDTCErrorInfo:0, ComM_ErrStatIBSSts01TimeoutDTCErrorInfo:0, ComM_ErrResIBSSts01TimeoutDTCErrorInfo:0]
          data-element=tec_ComM_IBSSts01CRCInfo_Bus, init-value=fields=[ComM_MonStatIBSSts01CRCErrorInfo:0, ComM_MonResIBSSts01CRCErrorInfo:0, ComM_ErrStatIBSSts01CRCErrorInfo:0, ComM_ErrResIBSSts01CRCErrorInfo:0]
          data-element=tec_ComM_IBSSts01E2ETimeoutInfo_Bus, init-value=fields=[ComM_MonStatIBSSts01E2ETimeoutInfo:0, ComM_MonResIBSSts01E2ETimeoutInfo:0, ComM_ErrStatIBSSts01E2ETimeoutInfo:0, ComM_ErrResIBSSts01E2ETimeoutInfo:0]
      RTE_P_ComM_BMSSts01ErrInfo_Bus: provided-interface=IF_ComM_BMSSts01ErrInfo_Bus
        provided-com-specs:
          data-element=tec_ComM_BMSSts01TimeoutInfo_Bus, init-value=fields=[ComM_MonStatBMSSts01TimeoutInfo:0, ComM_MonResBMSSts01TimeoutInfo:0, ComM_ErrStatBMSSts01TimeoutInfo:0, ComM_ErrResBMSSts01TimeoutInfo:0]
          data-element=tec_ComM_BMSSts01CRCDTCInfo_Bus, init-value=fields=[ComM_MonStatBMSSts01CRCDTCErrorInfo:0, ComM_MonResBMSSts01CRCDTCErrorInfo:0, ComM_ErrStatBMSSts01CRCDTCErrorInfo:0, ComM_ErrResBMSSts01CRCDTCErrorInfo:0]
          data-element=tec_ComM_BMSSts01CRCInfo_Bus, init-value=fields=[ComM_MonStatBMSSts01CRCErrorInfo:0, ComM_MonResBMSSts01CRCErrorInfo:0, ComM_ErrStatBMSSts01CRCErrorInfo:0, ComM_ErrResBMSSts01CRCErrorInfo:0]
          data-element=tec_ComM_BMSSts01TimeoutDTCInfo_Bus, init-value=fields=[ComM_MonStatBMSSts01TimeoutDTCErrorInfo:0, ComM_MonResBMSSts01TimeoutDTCErrorInfo:0, ComM_ErrStatBMSSts01TimeoutDTCErrorInfo:0, ComM_ErrResBMSSts01TimeoutDTCErrorInfo:0]
          data-element=tec_ComM_BMSSts01E2ETimeoutInfo_Bus, init-value=fields=[ComM_MonStatBMSSts01E2ETimeoutInfo:0, ComM_MonResBMSSts01E2ETimeoutInfo:0, ComM_ErrStatBMSSts01E2ETimeoutInfo:0, ComM_ErrResBMSSts01E2ETimeoutInfo:0]
      RTE_P_ComM_SysIRVal_kOhm: nonqueued-sender-com-spec{data-element=tec_ComM_SysIRVal_kOhm, init-value=0}, provided-interface=IF_ComM_SysIRVal_kOhm
      RTE_P_ComM_BMSIRDetnSts_Enum: nonqueued-sender-com-spec{data-element=tec_ComM_BMSIRDetnSts_Enum, init-value=0}, provided-interface=IF_ComM_BMSIRDetnSts_Enum
      RTE_P_ComM_BMSChrgSts_Enum: nonqueued-sender-com-spec{data-element=tec_ComM_BMSChrgSts_Enum, init-value=0}, provided-interface=IF_ComM_BMSChrgSts_Enum
      RTE_P_ComM_BMSBattUDc_V: nonqueued-sender-com-spec{data-element=tec_ComM_BMSBattUDc_V, init-value=0}, provided-interface=IF_ComM_BMSBattUDc_V
      RTE_P_ComM_ApptChrgMdlSts_Enum: nonqueued-sender-com-spec{data-element=tec_ComM_ApptChrgMdlSts_Enum, init-value=0}, provided-interface=IF_ComM_ApptChrgMdlSts_Enum
      RTE_P_ComM_SGWChrgCmd_Enum: nonqueued-sender-com-spec{data-element=tec_ComM_SGWChrgCmd_Enum, init-value=0}, provided-interface=IF_ComM_SGWChrgCmd_Enum
      RTE_P_ComM_IVIDchaSwtSts_Enum: nonqueued-sender-com-spec{data-element=tec_ComM_IVIDchaSwtSts_Enum, init-value=0}, provided-interface=IF_ComM_IVIDchaSwtSts_Enum
      RTE_P_ComM_IVIMaxChrgSOCSet_pct: nonqueued-sender-com-spec{data-element=tec_ComM_IVIMaxChrgSOCSet_pct, init-value=0}, provided-interface=IF_ComM_IVIMaxChrgSOCSet_pct
      RTE_P_ComM_IVIMinDchaSOCSet_Enum: nonqueued-sender-com-spec{data-element=tec_ComM_IVIMinDchaSOCSet_Enum, init-value=0}, provided-interface=IF_ComM_IVIMinDchaSOCSet_Enum
      RTE_P_ComM_IVIChrgCmd_Enum: nonqueued-sender-com-spec{data-element=tec_ComM_IVIChrgCmd_Enum, init-value=0}, provided-interface=IF_ComM_IVIChrgCmd_Enum
      RTE_P_ComM_IVIReqElectcLock_Enum: nonqueued-sender-com-spec{data-element=tec_ComM_IVIReqElectcLock_Enum, init-value=0}, provided-interface=IF_ComM_IVIReqElectcLock_Enum
      RTE_P_ComM_IBSEscOffSts_Enum: nonqueued-sender-com-spec{data-element=tec_ComM_IBSEscOffSts_Enum, init-value=0}, provided-interface=IF_ComM_IBSEscOffSts_Enum
      RTE_P_ComM_IBSRLSpd_kph: nonqueued-sender-com-spec{data-element=tec_ComM_IBSRLSpd_kph, init-value=0}, provided-interface=IF_ComM_IBSRLSpd_kph
      RTE_P_ComM_IBSRRSpd_kph: nonqueued-sender-com-spec{data-element=tec_ComM_IBSRRSpd_kph, init-value=0}, provided-interface=IF_ComM_IBSRRSpd_kph
      RTE_P_ComM_IBSRLSpdVld_Flg: nonqueued-sender-com-spec{data-element=tec_ComM_IBSRLSpdVld_Flg, init-value=0}, provided-interface=IF_ComM_IBSRLSpdVld_Flg
      RTE_P_ComM_IBSRRSpdVld_Flg: nonqueued-sender-com-spec{data-element=tec_ComM_IBSRRSpdVld_Flg, init-value=0}, provided-interface=IF_ComM_IBSRRSpdVld_Flg
      RTE_P_ComM_IBSRLMovgDir_Enum: nonqueued-sender-com-spec{data-element=tec_ComM_IBSRLMovgDir_Enum, init-value=0}, provided-interface=IF_ComM_IBSRLMovgDir_Enum
      RTE_P_ComM_IBSRRMovgDir_Enum: nonqueued-sender-com-spec{data-element=tec_ComM_IBSRRMovgDir_Enum, init-value=0}, provided-interface=IF_ComM_IBSRRMovgDir_Enum
      RTE_P_ComM_EPBWrkSts_Enum: nonqueued-sender-com-spec{data-element=tec_ComM_EPBWrkSts_Enum, init-value=0}, provided-interface=IF_ComM_EPBWrkSts_Enum
      RTE_P_ComM_BMSWrkMod_Enum: nonqueued-sender-com-spec{data-element=tec_ComM_BMSWrkMod_Enum, init-value=0}, provided-interface=IF_ComM_BMSWrkMod_Enum
      RTE_P_ComM_IBSTarGearReq_Enum: nonqueued-sender-com-spec{data-element=tec_ComM_IBSTarGearReq_Enum, init-value=0}, provided-interface=IF_ComM_IBSTarGearReq_Enum
      RTE_P_ComM_IVIGearReq_Enum: nonqueued-sender-com-spec{data-element=tec_ComM_IVIGearReq_Enum, init-value=0}, provided-interface=IF_ComM_IVIGearReq_Enum
      RTE_P_ComM_GearRNDBtnFltSts_Flg: nonqueued-sender-com-spec{data-element=tec_ComM_GearRNDBtnFltSts_Flg, init-value=0}, provided-interface=IF_ComM_GearRNDBtnFltSts_Flg
      RTE_P_ComM_GearPBtnFltSts_Flg: nonqueued-sender-com-spec{data-element=tec_ComM_GearPBtnFltSts_Flg, init-value=0}, provided-interface=IF_ComM_GearPBtnFltSts_Flg
      RTE_P_ComM_GearPBtn_Enum: nonqueued-sender-com-spec{data-element=tec_ComM_GearPBtn_Enum, init-value=0}, provided-interface=IF_ComM_GearPBtn_Enum
      RTE_P_ComM_GearRNDBtn_Enum: nonqueued-sender-com-spec{data-element=tec_ComM_GearRNDBtn_Enum, init-value=0}, provided-interface=IF_ComM_GearRNDBtn_Enum
    require port RTE_R_VehMot_RegenBrkLi_Flg: nonqueued-receiver-com-spec{data-element=tec_VehMot_RegenBrkLi_Flg, filter=data-filter-type=ALWAYS, init-value=0}, required-interface=IF_VehMot_RegenBrkLi_Flg
    require port RTE_R_VehMot_RegenBrkLiVld_Flg: nonqueued-receiver-com-spec{data-element=tec_VehMot_RegenBrkLiVld_Flg, filter=data-filter-type=ALWAYS, init-value=0}, required-interface=IF_VehMot_RegenBrkLiVld_Flg
    6 x provide port:
      RTE_P_ComM_YRSAxSts: nonqueued-sender-com-spec{data-element=tec_ComM_YRSAxSts, init-value=0}, provided-interface=IF_ComM_YRSAxSts
      RTE_P_ComM_YRSAx_mps2q: nonqueued-sender-com-spec{data-element=tec_ComM_YRSAx_mps2q, init-value=0}, provided-interface=IF_ComM_YRSAx_mps2q
      RTE_P_ComM_IBSFLMovgDir_Enum: nonqueued-sender-com-spec{data-element=tec_ComM_IBSFLMovgDir_Enum, init-value=0}, provided-interface=IF_ComM_IBSFLMovgDir_Enum
      RTE_P_ComM_IBSFRMovgDir_Enum: nonqueued-sender-com-spec{data-element=tec_ComM_IBSFRMovgDir_Enum, init-value=0}, provided-interface=IF_ComM_IBSFRMovgDir_Enum
      RTE_P_ComM_IBSVehSpdVld_Flg: nonqueued-sender-com-spec{data-element=tec_ComM_IBSVehSpdVld_Flg, init-value=0}, provided-interface=IF_ComM_IBSVehSpdVld_Flg
      RTE_P_ComM_IBSVehSpd_kph: nonqueued-sender-com-spec{data-element=tec_ComM_IBSVehSpd_kph, init-value=0}, provided-interface=IF_ComM_IBSVehSpd_kph
    5 x require port:
      RTE_R_VehMot_VehSpdVld_Flg: nonqueued-receiver-com-spec{data-element=tec_VehMot_VehSpdVld_Flg, filter=data-filter-type=ALWAYS, init-value=0}, required-interface=IF_VehMot_VehSpdVld_Flg
      RTE_R_VehMot_VehSpdABS_kph: nonqueued-receiver-com-spec{data-element=tec_VehMot_VehSpdABS_kph, filter=data-filter-type=ALWAYS, init-value=0}, required-interface=IF_VehMot_VehSpdABS_kph
      RTE_R_GearMgmt_TarGear_Enum: nonqueued-receiver-com-spec{data-element=tec_GearMgmt_TarGear_Enum, filter=data-filter-type=ALWAYS, init-value=0}, required-interface=IF_GearMgmt_TarGear_Enum
      RTE_R_HvMgmt_ReqModBMS_Enum: nonqueued-receiver-com-spec{data-element=tec_HvMgmt_ReqModBMS_Enum, filter=data-filter-type=ALWAYS, init-value=0}, required-interface=IF_HvMgmt_ReqModBMS_Enum
      RTE_R_ChrMgmt_ChrgSts_Enum: nonqueued-receiver-com-spec{data-element=tec_ChrMgmt_ChrgSts_Enum, filter=data-filter-type=ALWAYS, init-value=0}, required-interface=IF_ChrMgmt_ChrgSts_Enum
    11 x provide port:
      RTE_P_ComM_IBSBrkSts_Enum: nonqueued-sender-com-spec{data-element=tec_ComM_IBSBrkSts_Enum, init-value=0}, provided-interface=IF_ComM_IBSBrkSts_Enum
      RTE_P_ComM_IBSRbsReqTq_Nm: nonqueued-sender-com-spec{data-element=tec_ComM_IBSRbsReqTq_Nm, init-value=0}, provided-interface=IF_ComM_IBSRbsReqTq_Nm
      RTE_P_ComM_IBSRbsReqTqVld_Enum: nonqueued-sender-com-spec{data-element=tec_ComM_IBSRbsReqTqVld_Enum, init-value=0}, provided-interface=IF_ComM_IBSRbsReqTqVld_Enum
      RTE_P_ComM_IBSDecelReqAvl_Enum: nonqueued-sender-com-spec{data-element=tec_ComM_IBSDecelReqAvl_Enum, init-value=0}, provided-interface=IF_ComM_IBSDecelReqAvl_Enum
      RTE_P_ComM_ADCUAccMod_Enum: nonqueued-sender-com-spec{data-element=tec_ComM_ADCUAccMod_Enum, init-value=0}, provided-interface=IF_ComM_ADCUAccMod_Enum
      RTE_P_ComM_IBSRbsSts_Enum: nonqueued-sender-com-spec{data-element=tec_ComM_IBSRbsSts_Enum, init-value=0}, provided-interface=IF_ComM_IBSRbsSts_Enum
      RTE_P_ComM_IBSVlcActv_Flg: nonqueued-sender-com-spec{data-element=tec_ComM_IBSVlcActv_Flg, init-value=0}, provided-interface=IF_ComM_IBSVlcActv_Flg
      RTE_P_ComM_IBSVlcReqTq_Nm: nonqueued-sender-com-spec{data-element=tec_ComM_IBSVlcReqTq_Nm, init-value=0}, provided-interface=IF_ComM_IBSVlcReqTq_Nm
      RTE_P_ComM_IBSVlcReqTqVld_Flg: nonqueued-sender-com-spec{data-element=tec_ComM_IBSVlcReqTqVld_Flg, init-value=0}, provided-interface=IF_ComM_IBSVlcReqTqVld_Flg
      RTE_P_ComM_IBSApsReqTq_Nm: nonqueued-sender-com-spec{data-element=tec_ComM_IBSApsReqTq_Nm, init-value=0}, provided-interface=IF_ComM_IBSApsReqTq_Nm
      RTE_P_ComM_IBSApsReqTqVld_Enum: nonqueued-sender-com-spec{data-element=tec_ComM_IBSApsReqTqVld_Flg, init-value=0}, provided-interface=IF_ComM_IBSApsReqTqVld_Flg
    4 x require port:
      RTE_R_ModMgmt_HvSts_Enum: nonqueued-receiver-com-spec{data-element=tec_ModMgmt_HvSts_Enum, filter=data-filter-type=ALWAYS, init-value=0}, required-interface=IF_ModMgmt_HvSts_Enum
      RTE_R_ModMgmt_ActDrvMod_Enum: nonqueued-receiver-com-spec{data-element=tec_ModMgmt_ActDrvMod_Enum, filter=data-filter-type=ALWAYS, init-value=0}, required-interface=IF_ModMgmt_ActDrvMod_Enum
      RTE_R_ModMgmt_DrvModSwtWarn_Enum: nonqueued-receiver-com-spec{data-element=tec_ModMgmt_DrvModSwtWarn_Enum, filter=data-filter-type=ALWAYS, init-value=0}, required-interface=IF_ModMgmt_DrvModSwtWarn_Enum
      RTE_R_ModMgmt_ActRgnSts_Enum: nonqueued-receiver-com-spec{data-element=tec_ModMgmt_ActRgnSts_Enum, filter=data-filter-type=ALWAYS, init-value=0}, required-interface=IF_ModMgmt_ActRgnSts_Enum
    provide port RTE_P_ComM_IBSAvhSts_Enum: nonqueued-sender-com-spec{data-element=tec_ComM_IBSAvhSts_Enum, init-value=0}, provided-interface=IF_ComM_IBSAvhSts_Enum
    10 x require port:
      RTE_R_ChassisMgmt_AccrPedlVld_Flg: nonqueued-receiver-com-spec{data-element=tec_ChassisMgmt_AccrPedlVld_Flg, filter=data-filter-type=ALWAYS, init-value=0}, required-interface=IF_ChassisMgmt_AccrPedlVld_Flg
      RTE_R_ChassisMgmt_BrkCmpWarn_Enum: nonqueued-receiver-com-spec{data-element=tec_ChassisMgmt_BrkCmpWarn_Enum, filter=data-filter-type=ALWAYS, init-value=0}, required-interface=IF_ChassisMgmt_BrkCmpWarn_Enum
      RTE_R_ChassisMgmt_RgnTqCap_Nm: nonqueued-receiver-com-spec{data-element=tec_ChassisMgmt_RgnTqCap_Nm, filter=data-filter-type=ALWAYS, init-value=0}, required-interface=IF_ChassisMgmt_RgnTqCap_Nm
      RTE_R_ChassisMgmt_RgnTqCapVld_Flg: nonqueued-receiver-com-spec{data-element=tec_ChassisMgmt_RgnTqCapVld_Flg, filter=data-filter-type=ALWAYS, init-value=0}, required-interface=IF_ChassisMgmt_RgnTqCapVld_Flg
      RTE_R_ChassisMgmt_AccrPedlDesTq_Nm: nonqueued-receiver-com-spec{data-element=tec_ChassisMgmt_AccrPedlDesTq_Nm, filter=data-filter-type=ALWAYS, init-value=0}, required-interface=IF_ChassisMgmt_AccrPedlDesTq_Nm
      RTE_R_ChassisMgmt_IBSApsReqTqActv_Flg: nonqueued-receiver-com-spec{data-element=tec_ChassisMgmt_IBSApsReqTqActv_Flg, filter=data-filter-type=ALWAYS, init-value=0}, required-interface=IF_ChassisMgmt_IBSApsReqTqActv_Flg
      RTE_R_ChassisMgmt_IBSApsReqTqAvl_Flg: nonqueued-receiver-com-spec{data-element=tec_ChassisMgmt_IBSApsReqTqAvl_Flg, filter=data-filter-type=ALWAYS, init-value=0}, required-interface=IF_ChassisMgmt_IBSApsReqTqAvl_Flg
      RTE_R_ChassisMgmt_IBSVlcReqTqActv_Flg: nonqueued-receiver-com-spec{data-element=tec_ChassisMgmt_IBSVlcReqTqActv_Flg, filter=data-filter-type=ALWAYS, init-value=0}, required-interface=IF_ChassisMgmt_IBSVlcReqTqActv_Flg
      RTE_R_ChassisMgmt_DrvAsscCtrlOvrdSts_Flg: nonqueued-receiver-com-spec{data-element=tec_ChassisMgmt_DrvAsscCtrlOvrdSts_Flg, filter=data-filter-type=ALWAYS, init-value=0}, required-interface=IF_ChassisMgmt_DrvAsscCtrlOvrdSts_Flg
      RTE_R_ChassisMgmt_IBSVlcReqTqAvl_Flg: nonqueued-receiver-com-spec{data-element=tec_ChassisMgmt_IBSVlcReqTqAvl_Flg, filter=data-filter-type=ALWAYS, init-value=0}, required-interface=IF_ChassisMgmt_IBSVlcReqTqAvl_Flg
    provide port RTE_P_ComM_IBSApsTqActv_Flg: nonqueued-sender-com-spec{data-element=tec_ComM_IBSApsTqActv_Flg, init-value=0}, provided-interface=IF_ComM_IBSApsTqActv_Flg
    provide port RTE_P_ComM_IBSPlgrPrs_Bar: nonqueued-sender-com-spec{data-element=tec_ComM_IBSPlgrPrs_Bar, init-value=0}, provided-interface=IF_ComM_IBSPlgrPrs_Bar
    require port RTE_R_ChassisMgmt_VehDecelSpdSts_Flg: nonqueued-receiver-com-spec{data-element=tec_ChassisMgmt_VehDecelSpdSts_Flg, filter=data-filter-type=ALWAYS, init-value=0}, required-interface=IF_ChassisMgmt_VehDecelSpdSts_Flg
    require port RTE_R_ChassisMgmt_DesVehDecelSpd_mps2q: nonqueued-receiver-com-spec{data-element=tec_ChassisMgmt_DesVehDecelSpd_mps2q, filter=data-filter-type=ALWAYS, init-value=0}, required-interface=IF_ChassisMgmt_DesVehDecelSpd_mps2q
    provide port RTE_P_ComM_IVIEnaBrkCmpMod_Enum: nonqueued-sender-com-spec{data-element=tec_ComM_IVIEnaBrkCmpMod_Enum, init-value=0}, provided-interface=IF_ComM_IVIEnaBrkCmpMod_Enum
    require port RTE_R_FctSftyMon_AccrPedlTqOverFltInfo_Bus: nonqueued-receiver-com-spec{data-element=tec_FctSftyMon_AccrPedlTqOverFltInfo_Bus, filter=data-filter-type=ALWAYS, init-value=fields=[FctSftyMon_MonStatAccrPedlTqOverFltInfo:0, FctSftyMon_MonResAccrPedlTqOverFltInfo:0, FctSftyMon_ErrStatAccrPedlTqOverFltInfo:0, FctSftyMon_ErrResAccrPedlTqOverFltInfo:0]}, required-interface=IF_FctSftyMon_AccrPedlTqOverFltInfo_Bus
    require port RTE_R_FctSftyMon_CrpCtrlTqOverFltInfo_Bus: nonqueued-receiver-com-spec{data-element=tec_FctSftyMon_CrpCtrlTqOverFltInfo_Bus, filter=data-filter-type=ALWAYS, init-value=fields=[FctSftyMon_MonStatCrpCtrlTqOverFltInfo:0, FctSftyMon_MonResCrpCtrlTqOverFltInfo:0, FctSftyMon_ErrStatCrpCtrlTqOverFltInfo:0, FctSftyMon_ErrResCrpCtrlTqOverFltInfo:0]}, required-interface=IF_FctSftyMon_CrpCtrlTqOverFltInfo_Bus
    require port RTE_R_FctSftyMon_DesVehDecelSpdOverFltInfo_Bus: nonqueued-receiver-com-spec{data-element=tec_FctSftyMon_DesVehDecelSpdOverFltInfo_Bus, filter=data-filter-type=ALWAYS, init-value=fields=[FctSftyMon_MonStatDesVehDecelSpdOverFltInfo:0, FctSftyMon_MonResDesVehDecelSpdOverFltInfo:0, FctSftyMon_ErrStatDesVehDecelSpdOverFltInfo:0, FctSftyMon_ErrResDesVehDecelSpdOverFltInfo:0]}, required-interface=IF_FctSftyMon_DesVehDecelSpdOverFltInfo_Bus
    48 x provide port:
      RTE_P_ComM_IVIFwdVehSpdAllwd_Enum: nonqueued-sender-com-spec{data-element=tec_ComM_IVIFwdVehSpdAllwd_Enum, init-value=0}, provided-interface=IF_ComM_IVIFwdVehSpdAllwd_Enum
      RTE_P_ComM_IVIFwdMaxVehSpdLmtSwt_Enum: nonqueued-sender-com-spec{data-element=tec_ComM_IVIFwdMaxVehSpdLmtSwt_Enum, init-value=0}, provided-interface=IF_ComM_IVIFwdMaxVehSpdLmtSwt_Enum
      RTE_P_ComM_ADCUBodyReqMsgErrInfo_Bus: provided-interface=IF_ComM_ADCUBodyReqMsgErrInfo_Bus
        provided-com-specs:
          data-element=tec_ComM_ADCUBodyReqCRCDTCInfo_Bus, init-value=fields=[ComM_MonStatADCUBodyReqCRCDTCErrorInfo:0, ComM_MonResADCUBodyReqCRCDTCErrorInfo:0, ComM_ErrStatADCUBodyReqCRCDTCErrorInfo:0, ComM_ErrResADCUBodyReqCRCDTCErrorInfo:0]
          data-element=tec_ComM_ADCUBodyReqTimeoutDTCInfo_Bus, init-value=fields=[ComM_MonStatADCUBodyReqTimeoutDTCErrorInfo:0, ComM_MonResADCUBodyReqTimeoutDTCErrorInfo:0, ComM_ErrStatADCUBodyReqTimeoutDTCErrorInfo:0, ComM_ErrResADCUBodyReqTimeoutDTCErrorInfo:0]
      RTE_P_ComM_APTCTCUMsgErrInfo_Bus: provided-interface=IF_ComM_APTCTCUMsgErrInfo_Bus
        provided-com-specs:
          data-element=tec_ComM_APTCTCUTimeoutDTCInfo_Bus, init-value=fields=[ComM_MonStatAPTCTCUTimeoutDTCErrorInfo:0, ComM_MonResAPTCTCUTimeoutDTCErrorInfo:0, ComM_ErrStatAPTCTCUTimeoutDTCErrorInfo:0, ComM_ErrResAPTCTCUTimeoutDTCErrorInfo:0]
          data-element=tec_ComM_APTCTCUTimeoutInfo_Bus, init-value=fields=[ComM_MonStatAPTCTCUTimeoutInfo:0, ComM_MonResAPTCTCUTimeoutInfo:0, ComM_ErrStatAPTCTCUTimeoutInfo:0, ComM_ErrResAPTCTCUTimeoutInfo:0]
      RTE_P_ComM_BCM06MsgErrInfo_Bus: provided-interface=IF_ComM_BCM06MsgErrInfo_Bus
        provided-com-specs:
          data-element=tec_ComM_BCM06CRCDTCInfo_Bus, init-value=fields=[ComM_MonStatBCM06CRCDTCErrorInfo:0, ComM_MonResBCM06CRCDTCErrorInfo:0, ComM_ErrStatBCM06CRCDTCErrorInfo:0, ComM_ErrResBCM06CRCDTCErrorInfo:0]
          data-element=tec_ComM_BCM06TimeoutDTCInfo_Bus, init-value=fields=[ComM_MonStatBCM06TimeoutDTCErrorInfo:0, ComM_MonResBCM06TimeoutDTCErrorInfo:0, ComM_ErrStatBCM06TimeoutDTCErrorInfo:0, ComM_ErrResBCM06TimeoutDTCErrorInfo:0]
          data-element=tec_ComM_BCM06TimeoutInfo_Bus, init-value=fields=[ComM_MonStatBCM06TimeoutInfo:0, ComM_MonResBCM06TimeoutInfo:0, ComM_ErrStatBCM06TimeoutInfo:0, ComM_ErrResBCM06TimeoutInfo:0]
      RTE_P_ComM_DCMFL02MsgErrInfo_Bus: provided-interface=IF_ComM_DCMFL02MsgErrInfo_Bus
        provided-com-specs:
          data-element=tec_ComM_DCMFL02CRCDTCInfo_Bus, init-value=fields=[ComM_MonStatDCMFL02CRCDTCErrorInfo:0, ComM_MonResDCMFL02CRCDTCErrorInfo:0, ComM_ErrStatDCMFL02CRCDTCErrorInfo:0, ComM_ErrResDCMFL02CRCDTCErrorInfo:0]
          data-element=tec_ComM_DCMFL02TimeoutDTCInfo_Bus, init-value=fields=[ComM_MonStatDCMFL02TimeoutDTCErrorInfo:0, ComM_MonResDCMFL02TimeoutDTCErrorInfo:0, ComM_ErrStatDCMFL02TimeoutDTCErrorInfo:0, ComM_ErrResDCMFL02TimeoutDTCErrorInfo:0]
          data-element=tec_ComM_DCMFL02TimeoutInfo_Bus, init-value=fields=[ComM_MonStatDCMFL02TimeoutInfo:0, ComM_MonResDCMFL02TimeoutInfo:0, ComM_ErrStatDCMFL02TimeoutInfo:0, ComM_ErrResDCMFL02TimeoutInfo:0]
      RTE_P_ComM_MCUFailrCodMsgErrInfo_Bus: provided-interface=IF_ComM_MCUFailrCodMsgErrInfo_Bus
        provided-com-specs:
          data-element=tec_ComM_MCUFailrCodCRCDTCInfo_Bus, init-value=fields=[ComM_MonStatMCUFailrCodCRCDTCErrorInfo:0, ComM_MonResMCUFailrCodCRCDTCErrorInfo:0, ComM_ErrStatMCUFailrCodCRCDTCErrorInfo:0, ComM_ErrResMCUFailrCodCRCDTCErrorInfo:0]
          data-element=tec_ComM_MCUFailrCodTimeoutDTCInfo_Bus, init-value=fields=[ComM_MonStatMCUFailrCodTimeoutDTCErrorInfo:0, ComM_MonResMCUFailrCodTimeoutDTCErrorInfo:0, ComM_ErrStatMCUFailrCodTimeoutDTCErrorInfo:0, ComM_ErrResMCUFailrCodTimeoutDTCErrorInfo:0]
          tec_ComM_MCUFailrCodCRCInfo_Bus
          tec_ComM_MCUFailrCodE2ETimeoutInfo_Bus
      RTE_P_ComM_EVCOMSts01MsgErrInfo_Bus: provided-interface=IF_ComM_EVCOMSts01MsgErrInfo_Bus
        provided-com-specs:
          data-element=tec_ComM_EVCOMSts01TimeoutDTCInfo_Bus, init-value=fields=[ComM_MonStatEVCOMSts01TimeoutDTCErrorInfo:0, ComM_MonResEVCOMSts01TimeoutDTCErrorInfo:0, ComM_ErrStatEVCOMSts01TimeoutDTCErrorInfo:0, ComM_ErrResEVCOMSts01TimeoutDTCErrorInfo:0]
          data-element=tec_ComM_EVCOMSts01TimeoutInfo_Bus, init-value=fields=[ComM_MonStatEVCOMSts01TimeoutInfo:0, ComM_MonResEVCOMSts01TimeoutInfo:0, ComM_ErrStatEVCOMSts01TimeoutInfo:0, ComM_ErrResEVCOMSts01TimeoutInfo:0]
      RTE_P_ComM_PODDCDC01MsgErrInfo_Bus: provided-interface=IF_ComM_PODDCDC01MsgErrInfo_Bus
        provided-com-specs:
          data-element=tec_ComM_PODDCDC01TimeoutDTCInfo_Bus, init-value=fields=[ComM_MonStatPODDCDC01TimeoutDTCErrorInfo:0, ComM_MonResPODDCDC01TimeoutDTCErrorInfo:0, ComM_ErrStatPODDCDC01TimeoutDTCErrorInfo:0, ComM_ErrResPODDCDC01TimeoutDTCErrorInfo:0]
          data-element=tec_ComM_PODDCDC01TimeoutInfo_Bus, init-value=fields=[ComM_MonStatPODDCDC01TimeoutInfo:0, ComM_MonResPODDCDC01TimeoutInfo:0, ComM_ErrStatPODDCDC01TimeoutInfo:0, ComM_ErrResPODDCDC01TimeoutInfo:0]
      RTE_P_ComM_PODOBCChrgStatMsgErrInfo_Bus: provided-interface=IF_ComM_PODOBCChrgStatMsgErrInfo_Bus
        provided-com-specs:
          data-element=tec_ComM_PODOBCChrgStatTimeoutDTCInfo_Bus, init-value=fields=[ComM_MonStatPODOBCChrgStatTimeoutDTCErrorInfo:0, ComM_MonResPODOBCChrgStatTimeoutDTCErrorInfo:0, ComM_ErrStatPODOBCChrgStatTimeoutDTCErrorInfo:0, ComM_ErrResPODOBCChrgStatTimeoutDTCErrorInfo:0]
          data-element=tec_ComM_PODOBCChrgStatTimeoutInfo_Bus, init-value=fields=[ComM_MonStatPODOBCChrgStatTimeoutInfo:0, ComM_MonResPODOBCChrgStatTimeoutInfo:0, ComM_ErrStatPODOBCChrgStatTimeoutInfo:0, ComM_ErrResPODOBCChrgStatTimeoutInfo:0]
      RTE_P_ComM_SGWPT01MsgErrInfo_Bus: provided-interface=IF_ComM_SGWPT01MsgErrInfo_Bus
        provided-com-specs:
          data-element=tec_ComM_SGWPT01TimeoutDTCInfo_Bus, init-value=fields=[ComM_MonStatSGWPT01TimeoutDTCErrorInfo:0, ComM_MonResSGWPT01TimeoutDTCErrorInfo:0, ComM_ErrStatSGWPT01TimeoutDTCErrorInfo:0, ComM_ErrResSGWPT01TimeoutDTCErrorInfo:0]
          data-element=tec_ComM_SGWPT01TimeoutInfo_Bus, init-value=fields=[ComM_MonStatSGWPT01TimeoutInfo:0, ComM_MonResSGWPT01TimeoutInfo:0, ComM_ErrStatSGWPT01TimeoutInfo:0, ComM_ErrResSGWPT01TimeoutInfo:0]
      RTE_P_ComM_SGWTimMsgErrInfo_Bus: provided-interface=IF_ComM_SGWTimMsgErrInfo_Bus
        provided-com-specs:
          data-element=tec_ComM_SGWTimTimeoutDTCInfo_Bus, init-value=fields=[ComM_MonStatSGWTimTimeoutDTCErrorInfo:0, ComM_MonResSGWTimTimeoutDTCErrorInfo:0, ComM_ErrStatSGWTimTimeoutDTCErrorInfo:0, ComM_ErrResSGWTimTimeoutDTCErrorInfo:0]
          data-element=tec_ComM_SGWTimTimeoutInfo_Bus, init-value=fields=[ComM_MonStatSGWTimTimeoutInfo:0, ComM_MonResSGWTimTimeoutInfo:0, ComM_ErrStatSGWTimTimeoutInfo:0, ComM_ErrResSGWTimTimeoutInfo:0]
      RTE_P_ComM_TCU01MsgErrInfo_Bus: provided-interface=IF_ComM_TCU01MsgErrInfo_Bus
        provided-com-specs:
          data-element=tec_ComM_TCU01TimeoutDTCInfo_Bus, init-value=fields=[ComM_MonStatTCU01TimeoutDTCErrorInfo:0, ComM_MonResTCU01TimeoutDTCErrorInfo:0, ComM_ErrStatTCU01TimeoutDTCErrorInfo:0, ComM_ErrResTCU01TimeoutDTCErrorInfo:0]
          data-element=tec_ComM_TCU01TimeoutInfo_Bus, init-value=fields=[ComM_MonStatTCU01TimeoutInfo:0, ComM_MonResTCU01TimeoutInfo:0, ComM_ErrStatTCU01TimeoutInfo:0, ComM_ErrResTCU01TimeoutInfo:0]
      RTE_P_ComM_BattMaxTemp_C: nonqueued-sender-com-spec{data-element=tec_ComM_BMSBattMaxTemp_C, init-value=0}, provided-interface=IF_ComM_BattMaxTemp_C
      RTE_P_ComM_BattMinTemp_C: nonqueued-sender-com-spec{data-element=tec_ComM_BMSBattMinTemp_C, init-value=0}, provided-interface=IF_ComM_BattMinTemp_C
      RTE_P_ComM_BMSRemnChrgTim_min: nonqueued-sender-com-spec{data-element=tec_ComM_BMSRemnChrgTim_min, init-value=0}, provided-interface=IF_ComM_BMSRemnChrgTim_min
      RTE_P_ComM_BMSBattMaxChrgnUDc_V: nonqueued-sender-com-spec{data-element=tec_ComM_BMSBattMaxChrgnUDc_V, init-value=0}, provided-interface=IF_ComM_BMSBattMaxChrgnUDc_V
      RTE_P_ComM_CGW01MsgErrInfo_Bus: provided-interface=IF_ComM_CGW01MsgErrInfo_Bus
        provided-com-specs:
          data-element=tec_ComM_CGW01TimeoutDTCInfo_Bus, init-value=fields=[ComM_MonStatCGW01TimeoutDTCErrorInfo:0, ComM_MonResCGW01TimeoutDTCErrorInfo:0, ComM_ErrStatCGW01TimeoutDTCErrorInfo:0, ComM_ErrResCGW01TimeoutDTCErrorInfo:0]
          data-element=tec_ComM_CGW01TimeoutInfo_Bus, init-value=fields=[ComM_MonStatCGW01TimeoutInfo:0, ComM_MonResCGW01TimeoutInfo:0, ComM_ErrStatCGW01TimeoutInfo:0, ComM_ErrResCGW01TimeoutInfo:0]
          tec_ComM_CGW01CRCDTCInfo_Bus
      RTE_P_ComM_ChrgnRchTarCellUDc_Enum: nonqueued-sender-com-spec{data-element=tec_ComM_ChrgnRchTarCellUDc_Enum, init-value=0}, provided-interface=IF_ComM_ChrgnRchTarCellUDc_Enum
      RTE_P_ComM_ChrgnRchTarTotUDc_Enum: nonqueued-sender-com-spec{data-element=tec_ComM_ChrgnRchTarTotUDc_Enum, init-value=0}, provided-interface=IF_ComM_ChrgnRchTarTotUDc_Enum
      RTE_P_ComM_AbortFltBMSTemp_Enum: nonqueued-sender-com-spec=tec_ComM_AbortFltBMSTemp_Enum, provided-interface=IF_ComM_AbortFltBMSTemp_Enum
      RTE_P_ComM_AbortFltBattTemp_Enum: nonqueued-sender-com-spec=tec_ComM_AbortFltBattTemp_Enum, provided-interface=IF_ComM_AbortFltBattTemp_Enum
      RTE_P_ComM_AbortErrIDc_Enum: nonqueued-sender-com-spec=tec_ComM_AbortErrIDc_Enum, provided-interface=IF_ComM_AbortErrIDc_Enum
      RTE_P_ComM_ChrgnRchSetVal_Enum: nonqueued-sender-com-spec{data-element=tec_ComM_ChrgnRchSetVal_Enum, init-value=0}, provided-interface=IF_ComM_ChrgnRchSetVal_Enum
      RTE_P_ComM_AbortErrUDc_Enum: nonqueued-sender-com-spec=tec_ComM_AbortErrUDc_Enum, provided-interface=IF_ComM_AbortErrUDc_Enum
      RTE_P_ComM_BattChrgnModReq_Enum: nonqueued-sender-com-spec{data-element=tec_ComM_BattChrgnModReq_Enum, init-value=0}, provided-interface=IF_ComM_BattChrgnModReq_Enum
      RTE_P_ComM_BMSChrgCmplSts_Enum: nonqueued-sender-com-spec{data-element=tec_ComM_BMSChrgCmplSts_Enum, init-value=0}, provided-interface=IF_ComM_BMSChrgCmplSts_Enum
      RTE_P_ComM_BMSChrgReqSts_Enum: nonqueued-sender-com-spec{data-element=tec_ComM_BMSChrgReqSts_Enum, init-value=0}, provided-interface=IF_ComM_BMSChrgReqSts_Enum
      RTE_P_ComM_BMSBattLnkUDc_V: nonqueued-sender-com-spec{data-element=tec_ComM_BMSBattLnkUDc_V, init-value=0}, provided-interface=IF_ComM_BMSBattLnkUDc_V
      RTE_P_ComM_OBCCPIDcLmt_A: nonqueued-sender-com-spec{data-element=tec_ComM_OBCCPIDcLmt_A, init-value=0}, provided-interface=IF_ComM_OBCCPIDcLmt_A
      RTE_P_ComM_OBCCPSts_Enum: nonqueued-sender-com-spec{data-element=tec_ComM_OBCCPSts_Enum, init-value=0}, provided-interface=IF_ComM_OBCCPSts_Enum
      RTE_P_ComM_OBCCCIDcLmt_A: nonqueued-sender-com-spec{data-element=tec_ComM_OBCCCIDcLmt_A, init-value=0}, provided-interface=IF_ComM_OBCCCIDcLmt_A
      RTE_P_ComM_OBCCPPwmDuty_pct: nonqueued-sender-com-spec{data-element=tec_ComM_OBCCPPwmDuty_pct, init-value=0}, provided-interface=IF_ComM_OBCCPPwmDuty_pct
      RTE_P_ComM_ElectcLockSts_Enum: nonqueued-sender-com-spec{data-element=tec_ComM_ElectcLockSts_Enum, init-value=0}, provided-interface=IF_ComM_ElectcLockSts_Enum
      RTE_P_ComM_AcChrgPha_Enum: nonqueued-sender-com-spec=tec_ComM_AcChrgPha_Enum, provided-interface=IF_ComM_AcChrgPha_Enum
      RTE_P_ComM_S2SwtSts_Enum: nonqueued-sender-com-spec{data-element=tec_ComM_S2SwtSts_Enum, init-value=0}, provided-interface=IF_ComM_S2SwtSts_Enum
      RTE_P_ComM_OBCMaxAllwdIDc_A: nonqueued-sender-com-spec{data-element=tec_ComM_OBCMaxAllwdIDc_A, init-value=0}, provided-interface=IF_ComM_OBCMaxAllwdIDc_A
      RTE_P_ComM_OBCInpIAc_A: nonqueued-sender-com-spec{data-element=tec_ComM_OBCInpIAc_A, init-value=0}, provided-interface=IF_ComM_OBCInpIAc_A
      RTE_P_ComM_OBCInpUAc_V: nonqueued-sender-com-spec{data-element=tec_ComM_OBCInpUAc_V, init-value=0}, provided-interface=IF_ComM_OBCInpUAc_V
      RTE_P_ComM_PODDCFCUDc_V: nonqueued-sender-com-spec{data-element=tec_ComM_PODDCFCUDc_V, init-value=0}, provided-interface=IF_ComM_PODDCFCUDc_V
      RTE_P_ComM_DcInletATemp_C: nonqueued-sender-com-spec{data-element=tec_ComM_DcInletATemp_C, init-value=0}, provided-interface=IF_ComM_DcInletATemp_C
      RTE_P_ComM_DcInletBTemp_C: nonqueued-sender-com-spec{data-element=tec_ComM_DcInletBTemp_C, init-value=0}, provided-interface=IF_ComM_DcInletBTemp_C
      RTE_P_ComM_DcInletBSnsrSts_Enum: nonqueued-sender-com-spec{data-element=tec_ComM_DcInletBSnsrSts_Enum, init-value=0}, provided-interface=IF_ComM_DcInletBSnsrSts_Enum
      RTE_P_ComM_DcInletASnsrSts_Enum: nonqueued-sender-com-spec{data-element=tec_ComM_DcInletASnsrSts_Enum, init-value=0}, provided-interface=IF_ComM_DcInletASnsrSts_Enum
      RTE_P_ComM_TCUHvPwrSts_Enum: nonqueued-sender-com-spec{data-element=tec_ComM_TCUHvPwrSts_Enum, init-value=0}, provided-interface=IF_ComM_TCUHvPwrSts_Enum
      RTE_P_ComM_BCMImmoSts_Flg: nonqueued-sender-com-spec{data-element=tec_ComM_BCMImmoSts_Flg, init-value=0}, provided-interface=IF_ComM_BCMImmoSts_Flg
      RTE_P_ComM_TCUErrLvl_Enum: nonqueued-sender-com-spec{data-element=tec_ComM_TCUErrLvl_Enum, init-value=0}, provided-interface=IF_ComM_TCUErrLvl_Enum
      RTE_P_ComM_MCUErrLvl_Enum: nonqueued-sender-com-spec{data-element=tec_ComM_MCUErrLvl_Enum, init-value=0}, provided-interface=IF_ComM_MCUErrLvl_Enum
    23 x require port:
      RTE_R_EgyMgmt_TCUPwrAllwd_W: nonqueued-receiver-com-spec{data-element=tec_EgyMgmt_TCUPwrAllwd_W, filter=data-filter-type=ALWAYS, init-value=0}, required-interface=IF_EgyMgmt_TCUPwrAllwd_W
      RTE_R_EgyMgmt_DCDCPwrLmt_Kw: nonqueued-receiver-com-spec{data-element=tec_EgyMgmt_DCDCPwrLmt_Kw, filter=data-filter-type=ALWAYS, init-value=0}, required-interface=IF_EgyMgmt_DCDCPwrLmt_Kw
      RTE_R_EgyMgmt_AvgMCUPwrCnsCalcn_Kw: nonqueued-receiver-com-spec{data-element=tec_EgyMgmt_AvgMCUPwrCnsCalcn_Kw, filter=data-filter-type=ALWAYS, init-value=0}, required-interface=IF_EgyMgmt_AvgMCUPwrCnsCalcn_Kw
      RTE_R_EgyMgmt_PermtPckPTC_Flg: nonqueued-receiver-com-spec{data-element=tec_EgyMgmt_PermtPckPTC_Flg, filter=data-filter-type=ALWAYS, init-value=0}, required-interface=IF_EgyMgmt_PermtPckPTC_Flg
      RTE_R_TorqPahMgmt_FwdMaxVehSpd_Enum: nonqueued-receiver-com-spec{data-element=tec_TorqPahMgmt_FwdMaxVehSpd_Enum, filter=data-filter-type=ALWAYS, init-value=0}, required-interface=IF_TorqPahMgmt_FwdMaxVehSpd_Enum
      RTE_R_TorqPahMgmt_FwdMaxSpdSts_Flg: nonqueued-receiver-com-spec{data-element=tec_TorqPahMgmt_FwdMaxSpdSts_Flg, filter=data-filter-type=ALWAYS, init-value=0}, required-interface=IF_TorqPahMgmt_FwdMaxSpdSts_Flg
      RTE_R_ChrMgmt_ChrgProcCmt_Enum: nonqueued-receiver-com-spec{data-element=tec_ChrMgmt_ChrgProcCmt_Enum, filter=data-filter-type=ALWAYS, init-value=0}, required-interface=IF_ChrMgmt_ChrgProcCmt_Enum
      RTE_R_ChrMgmt_ChrgMemFlt_Flg: nonqueued-receiver-com-spec{data-element=tec_ChrMgmt_ChrgMemFlt_Flg, filter=data-filter-type=ALWAYS, init-value=0}, required-interface=IF_ChrMgmt_ChrgMemFlt_Flg
      RTE_R_ChassisMgmt_BrkCmpSts_Enum: nonqueued-receiver-com-spec{data-element=tec_ChassisMgmt_BrkCmpSts_Enum, filter=data-filter-type=ALWAYS, init-value=0}, required-interface=IF_ChassisMgmt_BrkCmpSts_Enum
      RTE_R_ChrMgmt_OBCSideSngDchaEgy_kWh: nonqueued-receiver-com-spec{data-element=tec_ChrMgmt_OBCSideSngDchaEgy_kWh, filter=data-filter-type=ALWAYS, init-value=0}, required-interface=IF_ChrMgmt_OBCSideSngDchaEgy_kWh
      RTE_R_ChrMgmt_VCUCalcdPODIDc_A: nonqueued-receiver-com-spec{data-element=tec_ChrMgmt_VCUCalcdPODIDc_A, filter=data-filter-type=ALWAYS, init-value=0}, required-interface=IF_ChrMgmt_VCUCalcdPODIDc_A
      RTE_R_ChrMgmt_ChrgTim_min: nonqueued-receiver-com-spec{data-element=tec_ChrMgmt_ChrgTim_min, filter=data-filter-type=ALWAYS, init-value=0}, required-interface=IF_ChrMgmt_ChrgTim_min
      RTE_R_DCChrMgmt_MaxChrgIDc_A: nonqueued-receiver-com-spec{data-element=tec_DCChrMgmt_MaxChrgIDc_A, filter=data-filter-type=ALWAYS, init-value=0}, required-interface=IF_DCChrMgmt_MaxChrgIDc_A
      RTE_R_DCChrMgmt_MinChrgIDc_A: nonqueued-receiver-com-spec{data-element=tec_DCChrMgmt_MinChrgIDc_A, filter=data-filter-type=ALWAYS, init-value=0}, required-interface=IF_DCChrMgmt_MinChrgIDc_A
      RTE_R_ChrMgmt_SngChrgEgy_kWh: nonqueued-receiver-com-spec{data-element=tec_ChrMgmt_SngChrgEgy_kWh, filter=data-filter-type=ALWAYS, init-value=0}, required-interface=IF_ChrMgmt_SngChrgEgy_kWh
      RTE_R_DCChrMgmt_MinChrgUDc_V: nonqueued-receiver-com-spec{data-element=tec_DCChrMgmt_MinChrgUDc_V, filter=data-filter-type=ALWAYS, init-value=0}, required-interface=IF_DCChrMgmt_MinChrgUDc_V
      RTE_R_DCChrMgmt_MaxChrgUDc_V: nonqueued-receiver-com-spec{data-element=tec_DCChrMgmt_MaxChrgUDc_V, filter=data-filter-type=ALWAYS, init-value=0}, required-interface=IF_DCChrMgmt_MaxChrgUDc_V
      RTE_R_HvMgmt_ReqDCDCMod_Enum: nonqueued-receiver-com-spec{data-element=tec_HvMgmt_ReqDCDCMod_Enum, filter=data-filter-type=ALWAYS, init-value=0}, required-interface=IF_HvMgmt_ReqDCDCMod_Enum
      RTE_R_HvMgmt_DCDCDmdLvUDc_V: nonqueued-receiver-com-spec{data-element=tec_HvMgmt_DCDCDmdLvUDc_V, filter=data-filter-type=ALWAYS, init-value=0}, required-interface=IF_HvMgmt_DCDCDmdLvUDc_V
      RTE_R_OBCMgmt_MnyUnlckCmt_Enum: nonqueued-receiver-com-spec{data-element=tec_OBCMgmt_MnyUnlckCmt_Enum, filter=data-filter-type=ALWAYS, init-value=0}, required-interface=IF_OBCMgmt_MnyUnlckCmt_Enum
      RTE_R_HvMgmt_ReqTCUMod_Enum: nonqueued-receiver-com-spec{data-element=tec_HvMgmt_ReqTCUMod_Enum, filter=data-filter-type=ALWAYS, init-value=0}, required-interface=IF_HvMgmt_ReqTCUMod_Enum
      RTE_R_ErrMgmt_InslaFlt_Bus: nonqueued-receiver-com-spec{data-element=tec_ErrMgmt_InslaFlt_Bus, filter=data-filter-type=ALWAYS, init-value=fields=[ErrMgmt_MonStatVehHVInsla:0, ErrMgmt_MonResVehHVInsla:0, ErrMgmt_ErrStatVehHVInsla:0, ErrMgmt_ErrResVehHVInsla:0]}, required-interface=IF_ErrMgmt_InslaFlt_Bus
      RTE_R_ErrMgmt_VehHVIL_Bus: nonqueued-receiver-com-spec{data-element=tec_ErrMgmt_VehHVIL_Bus, filter=data-filter-type=ALWAYS, init-value=fields=[ErrMgmt_MonStatVehHVIL:0, ErrMgmt_MonResVehHVIL:0, ErrMgmt_ErrStatVehHVIL:0, ErrMgmt_ErrResVehHVIL:0]}, required-interface=IF_ErrMgmt_VehHVIL_Bus
    provide port RTE_P_ComM_BMSBattRemnCp_Ah: nonqueued-sender-com-spec{data-element=tec_ComM_BMSBattRemnCp_Ah, init-value=0}, provided-interface=IF_ComM_BMSBattRemnCp_Ah
    5 x require port:
      RTE_R_ChassisMgmt_AccrPedlPosn_pct: nonqueued-receiver-com-spec{data-element=tec_ChassisMgmt_AccrPedlPosn_pct, filter=data-filter-type=ALWAYS, init-value=0}, required-interface=IF_ChassisMgmt_AccrPedlPosn_pct
      RTE_R_LvMgmt_BSBattUDcNorm_Flg: nonqueued-receiver-com-spec{data-element=tec_LvMgmt_BSBattUDcNorm_Flg, filter=data-filter-type=ALWAYS, init-value=0}, required-interface=IF_LvMgmt_BSBattUDcNorm_Flg
      RTE_R_DCChrMgmt_DcChrgStrt_Flg: nonqueued-receiver-com-spec{data-element=tec_DCChrMgmt_DcChrgStrt_Flg, filter=data-filter-type=ALWAYS, init-value=0}, required-interface=IF_DCChrMgmt_DcChrgStrt_Flg
      RTE_R_TorqPahMgmt_EmacQstyMinTq_Nm: nonqueued-receiver-com-spec{data-element=tec_TorqPahMgmt_EmacQstyMinTq_Nm, filter=data-filter-type=ALWAYS, init-value=0}, required-interface=IF_TorqPahMgmt_EmacQstyMinTq_Nm
      RTE_R_TorqPahMgmt_EmacQstyMaxTq_Nm: nonqueued-receiver-com-spec{data-element=tec_TorqPahMgmt_EmacQstyMaxTq_Nm, filter=data-filter-type=ALWAYS, init-value=0}, required-interface=IF_TorqPahMgmt_EmacQstyMaxTq_Nm
    provide port RTE_P_ComM_DCDCSide2OvrTempFlt_Flg: nonqueued-sender-com-spec{data-element=tec_ComM_DCDCSide2OvrTempFlt_Flg, init-value=0}, provided-interface=IF_ComM_DCDCSide2OvrTempFlt_Flg
    provide port RTE_P_ComM_OBCSide1OvrTempFlt_Flg: nonqueued-sender-com-spec{data-element=tec_ComM_OBCSide1OvrTempFlt_Flg, init-value=0}, provided-interface=IF_ComM_OBCSide1OvrTempFlt_Flg
    provide port RTE_P_ComM_OBCSide2OvrTempFlt_Flg: nonqueued-sender-com-spec{data-element=tec_ComM_OBCSide2OvrTempFlt_Flg, init-value=0}, provided-interface=IF_ComM_OBCSide2OvrTempFlt_Flg
    require port RTE_R_ErrMgmt_DrvMotTempOvrLamp_Bus: nonqueued-receiver-com-spec{data-element=tec_ErrMgmt_DrvMotTempOvrLamp_Bus, filter=data-filter-type=ALWAYS, init-value=fields=[ErrMgmt_MonStatMCUTempOvr:0, ErrMgmt_MonResMCUTempOvr:0, ErrMgmt_ErrStatMCUTempOvr:0, ErrMgmt_ErrResMCUTempOvr:0]}, required-interface=IF_ErrMgmt_DrvMotTempOvrLamp_Bus
    require port RTE_R_ErrMgmt_HvBattTempOvrLamp_Bus: nonqueued-receiver-com-spec{data-element=tec_ErrMgmt_HvBattTempOvrLamp_Bus, filter=data-filter-type=ALWAYS, init-value=fields=[ErrMgmt_MonStatBMSTempOvr:0, ErrMgmt_MonResBMSTempOvr:0, ErrMgmt_ErrStatBMSTempOvr:0, ErrMgmt_ErrResBMSTempOvr:0]}, required-interface=IF_ErrMgmt_HvBattTempOvrLamp_Bus
    provide port RTE_P_ComM_IBSBrkStsVld_Flg: nonqueued-sender-com-spec{data-element=tec_ComM_IBSBrkStsVld_Flg, init-value=0}, provided-interface=IF_ComM_IBSBrkStsVld_Flg
    28 x require port:
      RTE_R_ComM_BMSPNC15: nonqueued-receiver-com-spec{data-element=tec_ComM_BMSPNC15, filter=data-filter-type=ALWAYS, init-value=0}, required-interface=IF_ComM_BMSPNC15
      RTE_R_ComM_CGWPNC0: nonqueued-receiver-com-spec{data-element=tec_ComM_CGWPNC0, filter=data-filter-type=ALWAYS, init-value=0}, required-interface=IF_ComM_CGWPNC0
      RTE_R_ComM_BMSPNC16: nonqueued-receiver-com-spec{data-element=tec_ComM_BMSPNC16, filter=data-filter-type=ALWAYS, init-value=0}, required-interface=IF_ComM_BMSPNC16
      RTE_R_ComM_CGWPNC2: nonqueued-receiver-com-spec{data-element=tec_ComM_CGWPNC2, filter=data-filter-type=ALWAYS, init-value=0}, required-interface=IF_ComM_CGWPNC2
      RTE_R_ComM_CGWPNC1: nonqueued-receiver-com-spec{data-element=tec_ComM_CGWPNC1, filter=data-filter-type=ALWAYS, init-value=0}, required-interface=IF_ComM_CGWPNC1
      RTE_R_ComM_CGWPNC13: nonqueued-receiver-com-spec{data-element=tec_ComM_CGWPNC13, filter=data-filter-type=ALWAYS, init-value=0}, required-interface=IF_ComM_CGWPNC13
      RTE_R_ComM_CGWPNC3: nonqueued-receiver-com-spec{data-element=tec_ComM_CGWPNC3, filter=data-filter-type=ALWAYS, init-value=0}, required-interface=IF_ComM_CGWPNC3
      RTE_R_ComM_CGWPNC15: nonqueued-receiver-com-spec{data-element=tec_ComM_CGWPNC15, filter=data-filter-type=ALWAYS, init-value=0}, required-interface=IF_ComM_CGWPNC15
      RTE_R_ComM_CGWPNC14: nonqueued-receiver-com-spec{data-element=tec_ComM_CGWPNC14, filter=data-filter-type=ALWAYS, init-value=0}, required-interface=IF_ComM_CGWPNC14
      RTE_R_ComM_CGWPNC17: nonqueued-receiver-com-spec{data-element=tec_ComM_CGWPNC17, filter=data-filter-type=ALWAYS, init-value=0}, required-interface=IF_ComM_CGWPNC17
      RTE_R_ComM_CGWPNC16: nonqueued-receiver-com-spec{data-element=tec_ComM_CGWPNC16, filter=data-filter-type=ALWAYS, init-value=0}, required-interface=IF_ComM_CGWPNC16
      RTE_R_ComM_VCUPNC0: nonqueued-receiver-com-spec{data-element=tec_ComM_VCUPNC0, filter=data-filter-type=ALWAYS, init-value=0}, required-interface=IF_ComM_VCUPNC0
      RTE_R_ComM_CGWPNC21: nonqueued-receiver-com-spec{data-element=tec_ComM_CGWPNC21, filter=data-filter-type=ALWAYS, init-value=0}, required-interface=IF_ComM_CGWPNC21
      RTE_R_ComM_VCUPNC2: nonqueued-receiver-com-spec{data-element=tec_ComM_VCUPNC2, filter=data-filter-type=ALWAYS, init-value=0}, required-interface=IF_ComM_VCUPNC2
      RTE_R_ComM_VCUPNC1: nonqueued-receiver-com-spec{data-element=tec_ComM_VCUPNC1, filter=data-filter-type=ALWAYS, init-value=0}, required-interface=IF_ComM_VCUPNC1
      RTE_R_ComM_VCUPNC14: nonqueued-receiver-com-spec{data-element=tec_ComM_VCUPNC14, filter=data-filter-type=ALWAYS, init-value=0}, required-interface=IF_ComM_VCUPNC14
      RTE_R_ComM_VCUPNC13: nonqueued-receiver-com-spec{data-element=tec_ComM_VCUPNC13, filter=data-filter-type=ALWAYS, init-value=0}, required-interface=IF_ComM_VCUPNC13
      RTE_R_ComM_VCUPNC3: nonqueued-receiver-com-spec{data-element=tec_ComM_VCUPNC3, filter=data-filter-type=ALWAYS, init-value=0}, required-interface=IF_ComM_VCUPNC3
      RTE_R_ComM_VCUPNC17: nonqueued-receiver-com-spec{data-element=tec_ComM_VCUPNC17, filter=data-filter-type=ALWAYS, init-value=0}, required-interface=IF_ComM_VCUPNC17
      RTE_R_ComM_VCUPNC16: nonqueued-receiver-com-spec{data-element=tec_ComM_VCUPNC16, filter=data-filter-type=ALWAYS, init-value=0}, required-interface=IF_ComM_VCUPNC16
      RTE_R_ComM_VCUPNC21: nonqueued-receiver-com-spec{data-element=tec_ComM_VCUPNC21, filter=data-filter-type=ALWAYS, init-value=0}, required-interface=IF_ComM_VCUPNC21
      RTE_R_ErrMgmt_MCUFltLamp: nonqueued-receiver-com-spec{data-element=tec_ErrMgmt_MCUFltLamp, filter=data-filter-type=ALWAYS, init-value=0}, required-interface=IF_ErrMgmt_MCUFltLamp
      CCS_OutputCurrent: nonqueued-receiver-com-spec{data-element=CCS_OutputCurrent, init-value=0}, required-interface=CCS_OutputCurrent
      RTE_R_ChassisMgmt_OnePedlCtrlReqStdlSts_Flg: nonqueued-receiver-com-spec{data-element=tec_ChassisMgmt_OnePedlCtrlReqStdlSts_Flg, filter=data-filter-type=ALWAYS, init-value=0}, required-interface=IF_ChassisMgmt_OnePedlCtrlReqStdlSts_Flg
      RTE_R_ChassisMgmt_IBSIntvTqActv: nonqueued-receiver-com-spec{data-element=tec_ChassisMgmt_IBSIntvTqActv, filter=data-filter-type=ALWAYS, init-value=0}, required-interface=IF_ChassisMgmt_IBSIntvTqActv
      RTE_R_ChassisMgmt_VehStbCtrlTqAvl_Flg: nonqueued-receiver-com-spec{data-element=tec_ChassisMgmt_VehStbCtrlTqAvl_Flg, filter=data-filter-type=ALWAYS, init-value=0}, required-interface=IF_ChassisMgmt_VehStbCtrlTqAvl_Flg
      RTE_R_ComM_BSBattSOC_pct: nonqueued-receiver-com-spec{data-element=tec_ComM_BSBattSOC_pct, filter=data-filter-type=ALWAYS, init-value=0}, required-interface=IF_ComM_BSBattSOC_pct
      RTE_R_ComM_BSBatVltHlResInfo: nonqueued-receiver-com-spec{data-element=tec_ComM_BSBatVltHlResInfo, filter=data-filter-type=ALWAYS, init-value=0}, required-interface=IF_ComM_BSBatVltHlResInfo
    8 x provide port:
      RTE_P_ComM_CGWVehStatusInfo: nonqueued-sender-com-spec{data-element=tec_ComM_CGWVehStatusInfo, init-value=0}, provided-interface=IF_ComM_CGWVehStatusInfo
      RTE_P_ComM_IVIOdometerInfo: nonqueued-sender-com-spec{data-element=tec_ComM_IVIOdometerInfo, init-value=0}, provided-interface=IF_ComM_IVIOdometerInfo
      RTE_P_ComM_SGWTimeDayInfo: nonqueued-sender-com-spec{data-element=tec_ComM_SGWTimeDayInfo, init-value=0}, provided-interface=IF_ComM_SGWTimeDayInfo
      RTE_P_ComM_SGWTimeHourInfo: nonqueued-sender-com-spec{data-element=tec_ComM_SGWTimeHourInfo, init-value=0}, provided-interface=IF_ComM_SGWTimeHourInfo
      RTE_P_ComM_SGWTimeMinuteInfo: nonqueued-sender-com-spec{data-element=tec_ComM_SGWTimeMinuteInfo, init-value=0}, provided-interface=IF_ComM_SGWTimeMinuteInfo
      RTE_P_ComM_SGWTimeMonthInfo: nonqueued-sender-com-spec{data-element=tec_ComM_SGWTimeMonthInfo, init-value=0}, provided-interface=IF_ComM_SGWTimeMonthInfo
      RTE_P_ComM_SGWTimeSecondInfo: nonqueued-sender-com-spec{data-element=tec_ComM_SGWTimeSecondInfo, init-value=0}, provided-interface=IF_ComM_SGWTimeSecondInfo
      RTE_P_ComM_SGWTimeYearInfo: nonqueued-sender-com-spec{data-element=tec_ComM_SGWTimeYearInfo, init-value=0}, provided-interface=IF_ComM_SGWTimeYearInfo
    7 x require port:
      RTE_R_DiagApp_DisableDCMReqInfo: nonqueued-receiver-com-spec{data-element=tec_DiagApp_DisableDCMReqInfo, filter=data-filter-type=ALWAYS, init-value=0}, required-interface=IF_DiagApp_DisableDCMReqInfo
      RTE_R_ComM_CGWPNC4: nonqueued-receiver-com-spec{data-element=tec_ComM_CGWPNC4, filter=data-filter-type=ALWAYS, init-value=0}, required-interface=IF_ComM_CGWPNC4
      RTE_R_ComM_CGWPNC6: nonqueued-receiver-com-spec{data-element=tec_ComM_CGWPNC6, filter=data-filter-type=ALWAYS, init-value=0}, required-interface=IF_ComM_CGWPNC6
      RTE_R_ComM_CGWPNC5: nonqueued-receiver-com-spec{data-element=tec_ComM_CGWPNC5, filter=data-filter-type=ALWAYS, init-value=0}, required-interface=IF_ComM_CGWPNC5
      RTE_R_ComM_VCUPNC5: nonqueued-receiver-com-spec{data-element=tec_ComM_VCUPNC5, filter=data-filter-type=ALWAYS, init-value=0}, required-interface=IF_ComM_VCUPNC5
      RTE_R_ComM_VCUPNC4: nonqueued-receiver-com-spec{data-element=tec_ComM_VCUPNC4, filter=data-filter-type=ALWAYS, init-value=0}, required-interface=IF_ComM_VCUPNC4
      RTE_R_ComM_VCUPNC6: nonqueued-receiver-com-spec{data-element=tec_ComM_VCUPNC6, filter=data-filter-type=ALWAYS, init-value=0}, required-interface=IF_ComM_VCUPNC6
    provide port RTE_P_ComM_IBSCddActvInfo: nonqueued-sender-com-spec{data-element=tec_ComM_IBSCddActvInfo, init-value=0}, provided-interface=IF_ComM_IBSCddActvInfo
    4 x require port:
      RTE_R_ChassisMgmt_AccrPedlKdStsInfo: nonqueued-receiver-com-spec{data-element=tec_ChassisMgmt_AccrPedlKdStsInfo, filter=data-filter-type=ALWAYS, init-value=0}, required-interface=IF_ChassisMgmt_AccrPedlKdStsInfo
      RTE_R_ChassisMgmt_VirtAccrPedlPosnInfo: nonqueued-receiver-com-spec{data-element=tec_ChassisMgmt_VirtAccrPedlPosnInfo, filter=data-filter-type=ALWAYS, init-value=0}, required-interface=IF_ChassisMgmt_VirtAccrPedlPosnInfo
      RTE_R_ChassisMgmt_AccrPedlRawPosnInfo: nonqueued-receiver-com-spec{data-element=tec_ChassisMgmt_AccrPedlRawPosnInfo, filter=data-filter-type=ALWAYS, init-value=0}, required-interface=IF_ChassisMgmt_AccrPedlRawPosnInfo
      RTE_R_ChassisMgmt_VirtAccrPedlVldInfo: nonqueued-receiver-com-spec{data-element=tec_ChassisMgmt_VirtAccrPedlVldInfo, filter=data-filter-type=ALWAYS, init-value=0}, required-interface=IF_ChassisMgmt_VirtAccrPedlVldInfo
    provide port RTE_P_ComM_IVILVLimPopInfo: nonqueued-sender-com-spec{data-element=tec_ComM_IVILVLimPopInfo, init-value=0}, provided-interface=IF_ComM_IVILVLimPopInfo
    require port RTE_R_LvMgmt_VCUlimLvlInfo: nonqueued-receiver-com-spec{data-element=tec_LvMgmt_VCUlimLvlInfo, filter=data-filter-type=ALWAYS, init-value=0}, required-interface=IF_LvMgmt_VCUlimLvlInfo
    require port RTE_R_LvMgmt_ReachLimStdInfo: nonqueued-receiver-com-spec{data-element=tec_LvMgmt_ReachLimStdInfo, filter=data-filter-type=ALWAYS, init-value=0}, required-interface=IF_LvMgmt_ReachLimStdInfo
    20 x provide port:
      RTE_P_ComM_DrvrWarnLampStsInfo: nonqueued-sender-com-spec{data-element=tec_ComM_DrvrWarnLampStsInfo, init-value=0}, provided-interface=IF_ComM_DrvrWarnLampStsInfo
      RTE_P_ComM_PassWarnLampStsInfo: nonqueued-sender-com-spec{data-element=tec_ComM_PassWarnLampStsInfo, init-value=0}, provided-interface=IF_ComM_PassWarnLampStsInfo
      RTE_P_ComM_PassAirbStsInfo: nonqueued-sender-com-spec{data-element=tec_ComM_PassAirbStsInfo, init-value=0}, provided-interface=IF_ComM_PassAirbStsInfo
      RTE_P_ComM_DoorFLStsInfo: nonqueued-sender-com-spec{data-element=tec_ComM_DoorFLStsInfo, init-value=0}, provided-interface=IF_ComM_DoorFLStsInfo
      RTE_P_ComM_DoorFRStsInfo: nonqueued-sender-com-spec{data-element=tec_ComM_DoorFRStsInfo, init-value=0}, provided-interface=IF_ComM_DoorFRStsInfo
      RTE_P_ComM_DoorRLStsInfo: nonqueued-sender-com-spec{data-element=tec_ComM_DoorRLStsInfo, init-value=0}, provided-interface=IF_ComM_DoorRLStsInfo
      RTE_P_ComM_DoorRRStsInfo: nonqueued-sender-com-spec{data-element=tec_ComM_DoorRRStsInfo, init-value=0}, provided-interface=IF_ComM_DoorRRStsInfo
      RTE_P_ComM_BrkFldWarnStsInfo: nonqueued-sender-com-spec{data-element=tec_ComM_BrkFldWarnStsInfo, init-value=0}, provided-interface=IF_ComM_BrkFldWarnStsInfo
      RTE_P_ComM_RollrBenchModInfo: nonqueued-sender-com-spec{data-element=tec_ComM_RollrBenchModInfo, init-value=0}, provided-interface=IF_ComM_RollrBenchModInfo
      RTE_P_ComM_OBCLostSpcInfo: nonqueued-sender-com-spec{data-element=tec_ComM_OBCLostSpcInfo, init-value=0}, provided-interface=IF_ComM_OBCLostSpcInfo
      RTE_P_ComM_FLSeatBltRmnReqInfo: nonqueued-sender-com-spec{data-element=tec_ComM_FLSeatBltRmnReqInfo, init-value=0}, provided-interface=IF_ComM_FLSeatBltRmnReqInfo
      RTE_P_ComM_FRSeatBltRmnReqInfo: nonqueued-sender-com-spec{data-element=tec_ComM_FRSeatBltRmnReqInfo, init-value=0}, provided-interface=IF_ComM_FRSeatBltRmnReqInfo
      RTE_P_ComM_RLSeatBltRmnReqInfo: nonqueued-sender-com-spec{data-element=tec_ComM_RLSeatBltRmnReqInfo, init-value=0}, provided-interface=IF_ComM_RLSeatBltRmnReqInfo
      RTE_P_ComM_RRSeatBltRmnReqInfo: nonqueued-sender-com-spec{data-element=tec_ComM_RRSeatBltRmnReqInfo, init-value=0}, provided-interface=IF_ComM_RRSeatBltRmnReqInfo
      RTE_P_ComM_DCMFRMsgErrInfo_Bus: provided-interface=IF_ComM_DCMFRMsgErrInfo_Bus
        provided-com-specs:
          data-element=tec_ComM_DCMFRTimeoutInfo_Bus, init-value=fields=[ComM_MonStatDCMFRTimeoutInfo:0, ComM_MonResDCMFRTimeoutInfo:0, ComM_ErrStatDCMFRTimeoutInfo:0, ComM_ErrResDCMFRTimeoutInfo:0]
          tec_ComM_DCMFRTimeoutDTCInfo_Bus
      RTE_P_ComM_DCMRLMsgErrInfo_Bus: provided-interface=IF_ComM_DCMRLMsgErrInfo_Bus
        provided-com-specs:
          data-element=tec_ComM_DCMRLTimeoutInfo_Bus, init-value=fields=[ComM_MonStatDCMRLTimeoutInfo:0, ComM_MonResDCMRLTimeoutInfo:0, ComM_ErrStatDCMRLTimeoutInfo:0, ComM_ErrResDCMRLTimeoutInfo:0]
          tec_ComM_DCMRLTimeoutDTCInfo_Bus
      RTE_P_ComM_DCMRRMsgErrInfo_Bus: provided-interface=IF_ComM_DCMRRMsgErrInfo_Bus
        provided-com-specs:
          data-element=tec_ComM_DCMRRTimeoutInfo_Bus, init-value=fields=[ComM_MonStatDCMRRTimeoutInfo:0, ComM_MonResDCMRRTimeoutInfo:0, ComM_ErrStatDCMRRTimeoutInfo:0, ComM_ErrResDCMRRTimeoutInfo:0]
          tec_ComM_DCMRRTimeoutDTCInfo_Bus
      RTE_P_ComM_BCM05MsgErrInfo_Bus: provided-interface=IF_ComM_BCM05MsgErrInfo_Bus
        provided-com-specs:
          data-element=tec_ComM_BCM05CRCDTCInfo_Bus, init-value=fields=[ComM_MonStatBCM05CRCDTCErrorInfo:0, ComM_MonResBCM05CRCDTCErrorInfo:0, ComM_ErrStatBCM05CRCDTCErrorInfo:0, ComM_ErrResBCM05CRCDTCErrorInfo:0]
          data-element=tec_ComM_BCM05TimeoutDTCInfo_Bus, init-value=fields=[ComM_MonStatBCM05TimeoutDTCErrorInfo:0, ComM_MonResBCM05TimeoutDTCErrorInfo:0, ComM_ErrStatBCM05TimeoutDTCErrorInfo:0, ComM_ErrResBCM05TimeoutDTCErrorInfo:0]
      RTE_P_ComM_IBSSysStsInfo: nonqueued-sender-com-spec{data-element=tec_ComM_IBSSysStsInfo, init-value=0}, provided-interface=IF_ComM_IBSSysStsInfo
      RTE_P_ComM_EBDFltStsInfo: nonqueued-sender-com-spec{data-element=tec_ComM_EBDFltStsInfo, init-value=0}, provided-interface=IF_ComM_EBDFltStsInfo
    require port RTE_R_EgyMgmt_V2LDisChgPwrLmtInfo: nonqueued-receiver-com-spec{data-element=tec_EgyMgmt_V2LDisChgPwrLmtInfo, filter=data-filter-type=ALWAYS, init-value=0}, required-interface=IF_EgyMgmt_V2LDisChgPwrLmtInfo
    require port RTE_R_LvMgmt_KL15CtrlReq_Flg: nonqueued-receiver-com-spec{data-element=tec_LvMgmt_KL15CtrlReq_Flg, filter=data-filter-type=ALWAYS, init-value=0}, required-interface=IF_LvMgmt_KL15CtrlReq_Flg
    provide port RTE_P_ComM_OBCChrgOutpPwrAvl_Kw: nonqueued-sender-com-spec{data-element=tec_ComM_OBCChrgOutpPwrAvl_Kw, init-value=0}, provided-interface=IF_ComM_OBCChrgOutpPwrAvl_Kw
    require port RTE_R_ChrMgmt_PosRlyReqSts_Enum: nonqueued-receiver-com-spec{data-element=tec_ChrMgmt_PosRlyReqSts_Enum, filter=data-filter-type=ALWAYS, init-value=0}, required-interface=IF_ChrMgmt_PosRlyReqSts_Enum
    provide port RTE_P_ComM_IBSTcsFltSts_Flg: nonqueued-sender-com-spec{data-element=tec_ComM_IBSTcsFltSts_Flg, init-value=0}, provided-interface=IF_ComM_IBSTcsFltSts_Flg
    require port RTE_R_DCChrMgmt_DCFCClsReq_Flg: nonqueued-receiver-com-spec{data-element=tec_DCChrMgmt_DCFCClsReq_Flg, filter=data-filter-type=ALWAYS, init-value=0}, required-interface=IF_DCChrMgmt_DCFCClsReq_Flg
    require port RTE_R_LvMgmt_AppNMReqInfo: nonqueued-receiver-com-spec{data-element=tec_LvMgmt_AppNMReqInfo, filter=data-filter-type=ALWAYS, init-value=0}, required-interface=IF_LvMgmt_AppNMReqInfo
    provide port RTE_P_ComM_ACUYawRate: nonqueued-sender-com-spec{data-element=tec_ComM_ACUYawRate, init-value=0}, provided-interface=IF_ComM_ACUYawRate
    4 x require port:
      RTE_R_ComM_TriggerASWMsgReqInfo: nonqueued-receiver-com-spec{data-element=tec_ComM_TriggerASWMsgReqInfo, filter=data-filter-type=ALWAYS, init-value=0}, required-interface=IF_ComM_TriggerASWMsgReqInfo
      RTE_R_TorqPahMgmt_MotDampLmtTq: nonqueued-receiver-com-spec{data-element=tec_TorqPahMgmt_MotDampLmtTq, filter=data-filter-type=ALWAYS, init-value=0}, required-interface=IF_TorqPahMgmt_MotDampLmtTq
      RTE_R_LvMgmt_IndicatorLightStsInfo: nonqueued-receiver-com-spec{data-element=tec_LvMgmt_IndicatorLightStsInfo, filter=data-filter-type=ALWAYS, init-value=0}, required-interface=IF_LvMgmt_IndicatorLightStsInfo
      RTE_R_ComM_BSBatCrnt: nonqueued-receiver-com-spec{data-element=tec_ComM_BSBatCrnt, filter=data-filter-type=ALWAYS, init-value=0}, required-interface=IF_ComM_BSBatCrnt
    24 x provide port:
      RTE_P_ComM_PODDCDC02Update: nonqueued-sender-com-spec{data-element=tec_ComM_PODDCDC02Update, init-value=0}, provided-interface=IF_ComM_PODDCDC02Update
      RTE_P_ComM_PODOBCSts03Update: nonqueued-sender-com-spec{data-element=tec_ComM_PODOBCSts03Update, init-value=0}, provided-interface=IF_ComM_PODOBCSts03Update
      RTE_P_ComM_IVIVrState: nonqueued-sender-com-spec{data-element=tec_ComM_IVIVrState, init-value=0}, provided-interface=IF_ComM_IVIVrState
      RTE_P_ComM_ADCURemPrkMod: nonqueued-sender-com-spec{data-element=tec_ComM_ADCURemPrkMod, init-value=0}, provided-interface=IF_ComM_ADCURemPrkMod
      RTE_P_ComM_ADCUDAMod: nonqueued-sender-com-spec{data-element=tec_ComM_ADCUDAMod, init-value=0}, provided-interface=IF_ComM_ADCUDAMod
      RTE_P_ComM_DCMAmbTemp: nonqueued-sender-com-spec{data-element=tec_ComM_DCMAmbTemp, init-value=0}, provided-interface=IF_ComM_DCMAmbTemp
      RTE_P_ComM_DCMAmbTempVld: nonqueued-sender-com-spec{data-element=tec_ComM_DCMAmbTempVld, init-value=0}, provided-interface=IF_ComM_DCMAmbTempVld
      RTE_P_ComM_TCU01Update: nonqueued-sender-com-spec{data-element=tec_ComM_TCU01Update, init-value=0}, provided-interface=IF_ComM_TCU01Update
      RTE_P_ComM_MCUFailCodeUpdate: nonqueued-sender-com-spec{data-element=tec_ComM_MCUFailCodeUpdate, init-value=0}, provided-interface=IF_ComM_MCUFailCodeUpdate
      RTE_P_ComM_ADCUDAMsgErrInfo_Bus: provided-interface=IF_ComM_ADCUDAMsgErrInfo_Bus
        provided-com-specs:
          data-element=tec_ComM_ADCUDATimeoutDTCInfo_Bus, init-value=fields=[ComM_MonStatADCUDATimeoutDTCErrorInfo:0, ComM_MonResADCUDATimeoutDTCErrorInfo:0, ComM_ErrStatADCUDATimeoutDTCErrorInfo:0, ComM_ErrResADCUDATimeoutDTCErrorInfo:0]
          data-element=tec_ComM_ADCUDACRCDTCInfo_Bus, init-value=fields=[ComM_MonStatADCUDACRCDTCErrorInfo:0, ComM_MonResADCUDACRCDTCErrorInfo:0, ComM_ErrStatADCUDACRCDTCErrorInfo:0, ComM_ErrResADCUDACRCDTCErrorInfo:0]
      RTE_P_ComM_SGW16MsgErrInfo_Bus: provided-interface=IF_ComM_SGW16MsgErrInfo_Bus
        provided-com-specs:
          data-element=tec_ComM_SGW16TimeoutInfo_Bus, init-value=fields=[ComM_MonStatSGW16TimeoutInfo:0, ComM_MonResSGW16TimeoutInfo:0, ComM_ErrStatSGW16TimeoutInfo:0, ComM_ErrResSGW16TimeoutInfo:0]
          data-element=tec_ComM_SGW16TimeoutDTCInfo_Bus, init-value=fields=[ComM_MonStatSGW16TimeoutDTCErrorInfo:0, ComM_MonResSGW16TimeoutDTCErrorInfo:0, ComM_ErrStatSGW16CTimeoutDTCErrorInfo:0, ComM_ErrResSGW16TimeoutDTCErrorInfo:0]
      RTE_P_ComM_BMSPTCRlyStsInfo: nonqueued-sender-com-spec{data-element=tec_ComM_BMSPTCRlyStsInfo, init-value=0}, provided-interface=IF_ComM_BMSPTCRlyStsInfo
      RTE_P_ComM_SGW17MsgErrInfo_Bus: provided-interface=IF_ComM_SGW17MsgErrInfo_Bus
        provided-com-specs:
          data-element=tec_ComM_SGW17TimeoutDTCInfo_Bus, init-value=fields=[ComM_MonStatSGW17TimeoutDTCErrorInfo:0, ComM_MonResSGW17TimeoutDTCErrorInfo:0, ComM_ErrStatSGW17TimeoutDTCErrorInfo:0, ComM_ErrResSGW17TimeoutDTCErrorInfo:0]
          data-element=tec_ComM_SGW17TimeoutInfo_Bus, init-value=fields=[ComM_MonStatSGW17TimeoutInfo:0, ComM_MonResSGW17TimeoutInfo:0, ComM_ErrStatSGW17TimeoutInfo:0, ComM_ErrResSGW17TimeoutInfo:0]
      RTE_P_ComM_IBSAPSMsgErrInfo_Bus: provided-interface=IF_ComM_IBSAPSMsgErrInfo_Bus
        provided-com-specs:
          data-element=tec_ComM_IBSAPSTimeoutDTCInfo_Bus, init-value=fields=[ComM_MonStatIBSAPSTimeoutDTCErrorInfo:0, ComM_MonResIBSAPSTimeoutDTCErrorInfo:0, ComM_ErrStatIBSAPSTimeoutDTCErrorInfo:0, ComM_ErrResIBSAPSTimeoutDTCErrorInfo:0]
          data-element=tec_ComM_IBSAPSCRCDTCInfo_Bus, init-value=fields=[ComM_MonStatIBSAPSCRCDTCErrorInfo:0, ComM_MonResIBSAPSCRCDTCErrorInfo:0, ComM_ErrStatIBSAPSCRCDTCErrorInfo:0, ComM_ErrResIBSAPSCRCDTCErrorInfo:0]
      RTE_P_ComM_ADCUAEB01MsgErrInfo_Bus: provided-interface=IF_ComM_ADCUAEB01MsgErrInfo_Bus
        provided-com-specs:
          data-element=tec_ComM_ADCUAEB01TimeoutDTCInfo_Bus, init-value=fields=[ComM_MonStatADCUAEB01TimeoutDTCErrorInfo:0, ComM_MonResADCUAEB01TimeoutDTCErrorInfo:0, ComM_ErrStatADCUAEB01TimeoutDTCErrorInfo:0, ComM_ErrResADCUAEB01TimeoutDTCErrorInfo:0]
          data-element=tec_ComM_ADCUAEB01CRCDTCInfo_Bus, init-value=fields=[ComM_MonStatADCUAEB01CRCDTCErrorInfo:0, ComM_MonResADCUAEB01CRCDTCErrorInfo:0, ComM_ErrStatADCUAEB01CRCDTCErrorInfo:0, ComM_ErrResADCUAEB01CRCDTCErrorInfo:0]
      RTE_P_ComM_ADCUAPS01MsgErrInfo_Bus: provided-interface=IF_ComM_ADCUAPS01MsgErrInfo_Bus
        provided-com-specs:
          data-element=tec_ComM_ADCUAPS01TimeoutDTCInfo_Bus, init-value=fields=[ComM_MonStatADCUAPS01TimeoutDTCErrorInfo:0, ComM_MonResADCUAPS01TimeoutDTCErrorInfo:0, ComM_ErrStatADCUAPS01TimeoutDTCErrorInfo:0, ComM_ErrResADCUAPS01TimeoutDTCErrorInfo:0]
          data-element=tec_ComM_ADCUAPS01CRCDTCInfo_Bus, init-value=fields=[ComM_MonStatADCUAPS01CRCDTCErrorInfo:0, ComM_MonResADCUAPS01CRCDTCErrorInfo:0, ComM_ErrStatADCUAPS01CRCDTCErrorInfo:0, ComM_ErrResADCUAPS01CRCDTCErrorInfo:0]
      RTE_P_ComM_ACUInfoUpdate: nonqueued-sender-com-spec{data-element=tec_ComM_ACUInfoUpdate, init-value=0}, provided-interface=IF_ComM_ACUInfoUpdate
      RTE_P_ComM_BMSSts01Update: nonqueued-sender-com-spec{data-element=tec_ComM_BMSSts01Update, init-value=0}, provided-interface=IF_ComM_BMSSts01Update
      RTE_P_ComM_ADCUAEBSt: nonqueued-sender-com-spec{data-element=tec_ComM_ADCUAEBSt, init-value=0}, provided-interface=IF_ComM_ADCUAEBSt
      RTE_P_ComM_ADCUPrkMod: nonqueued-sender-com-spec{data-element=tec_ComM_ADCUPrkMod, init-value=0}, provided-interface=IF_ComM_ADCUPrkMod
      RTE_P_ComM_IBSEPBControllerSts: nonqueued-sender-com-spec{data-element=tec_ComM_IBSEPBControllerSts, init-value=0}, provided-interface=IF_ComM_IBSEPBControllerSts
      RTE_P_ComM_IBSSUBEPBWrkSts: nonqueued-sender-com-spec{data-element=tec_ComM_IBSSUBEPBWrkSts, init-value=0}, provided-interface=IF_ComM_IBSSUBEPBWrkSts
      RTE_P_ComM_IBSSUBEPBControllerSts: nonqueued-sender-com-spec{data-element=tec_ComM_IBSSUBEPBControllerSts, init-value=0}, provided-interface=IF_ComM_IBSSUBEPBControllerSts
      RTE_P_ComM_SGWSysRdyReq: nonqueued-sender-com-spec{data-element=tec_ComM_SGWSysRdyReq, init-value=0}, provided-interface=IF_ComM_SGWSysRdyReq
    require port RTE_R_FctSftyMon_EPBReq: nonqueued-receiver-com-spec{data-element=tec_FctSftyMon_EPBReq, filter=data-filter-type=ALWAYS, init-value=0}, required-interface=IF_FctSftyMon_EPBReq
    provide port RTE_P_ComM_SGWDchaSwtSts: nonqueued-sender-com-spec=tec_ComM_SGWDchaSwtSts, provided-interface=IF_ComM_SGWDchaSwtSts
    provide port RTE_P_ComM_IBSDtcFltSts: nonqueued-sender-com-spec=tec_ComM_IBSDtcFltSts, provided-interface=IF_ComM_IBSDtcFltSts
    80 x require port:
      RTE_R_ChassisMgmt_CrpCtrlDesTq_Nm: nonqueued-receiver-com-spec{data-element=tec_ChassisMgmt_CrpCtrlDesTq_Nm, filter=data-filter-type=ALWAYS, init-value=0}, required-interface=IF_ChassisMgmt_CrpCtrlDesTq_Nm
      RTE_R_TorqPahMgmt_MaxVehSpdLmtTq_Nm: nonqueued-receiver-com-spec{data-element=tec_TorqPahMgmt_MaxVehSpdLmtTq_Nm, filter=data-filter-type=ALWAYS, init-value=0}, required-interface=IF_TorqPahMgmt_MaxVehSpdLmtTq_Nm
      SG_SGW_PT_01_SigGroup: nonqueued-receiver-com-spec{data-element=SG_SGW_PT_01_SigGroup, enable-update=true, init-value=fields=[IVI_AppointChargeCmd:0, IVI_ForwardVmaxlimitSw:0, IVI_LockACPlug:0, IVI_LV_LimitPop:0]}, required-interface=SG_SGW_PT_01_SigGroup
      SG_POD_DCDC_02_SigGroup: nonqueued-receiver-com-spec{data-element=SG_POD_DCDC_02_SigGroup, enable-update=true, init-value=fields=[POD_DCDC_FaultLevel:0, POD_DCDC_Side2Overtempfault:0]}, required-interface=SG_POD_DCDC_02_SigGroup
      SG_SGW_Time_SigGroup: nonqueued-receiver-com-spec{data-element=SG_SGW_Time_SigGroup, enable-update=true, init-value=fields=[SGW_TimeInfoDay:1, SGW_TimeInfoHour:0, SGW_TimeInfoMinute:0, SGW_TimeInfoMonth:1, SGW_TimeInfoSecond:0, SGW_TimeInfoYear:0, SGW_TimeValid:1]}, required-interface=SG_SGW_Time_SigGroup
      SG_BMS_CellVoltage_SigGroup: nonqueued-receiver-com-spec{data-element=SG_BMS_CellVoltage_SigGroup, enable-update=true, filter=data-filter-type=ALWAYS, init-value=fields=[BMS_MaxCellVoltage:0, BMS_MaxCellVoltageModuleNO:0, BMS_MaxCellVoltageNO:0, BMS_MinCellVoltage:0]}, required-interface=SG_BMS_CellVoltage_SigGroup_1
      SG_IBS_WheelSpeed_01_SigGroup: nonqueued-receiver-com-spec{data-element=SG_IBS_WheelSpeed_01_SigGroup, uses-end-to-end-protection=true, enable-update=true, filter=data-filter-type=ALWAYS, init-value=fields=[Checksum_0B0:0, IBS_FLMovingDirection:0, IBS_FRMovingDirection:0, MessageCounter_0B0:0, IBS_FLWheelPulseCounter:0, IBS_FLWheelSpeed:0, IBS_FLWheelSpeed_Fault:0, IBS_FRWheelPulseCounter:0, IBS_FRWheelSpeed:0, IBS_FRWheelSpeed_Fault:0]}, required-interface=SG_IBS_WheelSpeed_01_SigGroup_1
      SG_CGW_01_SigGroup: nonqueued-receiver-com-spec{data-element=SG_CGW_01_SigGroup, uses-end-to-end-protection=true, enable-update=true, filter=data-filter-type=ALWAYS, init-value=fields=[CGW_VehicleState:0, Checksum_278:0, MessageCounter_278:0]}, required-interface=SG_CGW_01_SigGroup
      SG_IBS_VCU_MotorControl_SigGroup_CAN: nonqueued-receiver-com-spec{data-element=SG_IBS_VCU_MotorControl_SigGroup, uses-end-to-end-protection=true, enable-update=true, filter=data-filter-type=ALWAYS, init-value=fields=[IBS_WLTorqueIncrReq:0, IBS_WLTorqueIncrReqSts:0, IBS_WLTorqueRedReq:0, IBS_WLTorqueRedReqSts:0, Checksum_090:0, MessageCounter_090:0]}, required-interface=SG_IBS_VCU_MotorControl_SigGroup
      SG_SGW_04_SigGroup: nonqueued-receiver-com-spec{data-element=SG_SGW_04_SigGroup, enable-update=true, init-value=fields=SGW_RemoteHVCtrlReq:0}, required-interface=SG_SGW_04_SigGroup
      SG_PRND_SigGroup: nonqueued-receiver-com-spec{data-element=SG_PRND_SigGroup, uses-end-to-end-protection=true, enable-update=true, filter=data-filter-type=ALWAYS, init-value=fields=[Checksum_248:0, MessageCounter_248:0, PRND_Pbutton:0, PRND_Pbutton_FaultSts:0, PRND_RNDbutton:0, PRND_RNDbutton_FaultSts:0]}, required-interface=SG_PRND_SigGroup
      SG_DCM_FR_SigGroup: nonqueued-receiver-com-spec{data-element=SG_DCM_FR_SigGroup, enable-update=true, init-value=fields=DCM_FR_DoorFRSts:0}, required-interface=SG_DCM_FR_SigGroup
      SG_CGW_VIN3VER_SigGroup: nonqueued-receiver-com-spec{data-element=SG_CGW_VIN3VER_SigGroup, enable-update=true, init-value=fields=[CGW_VERSION1:0, CGW_VERSION2:0, CGW_VIN16:0]}, required-interface=SG_CGW_VIN3VER_SigGroup
      SG_BMS_ErrorInfo_SigGroup: nonqueued-receiver-com-spec{data-element=SG_BMS_ErrorInfo_SigGroup, enable-update=true, init-value=fields=[BMS_ErrorCellHighTemp:0, BMS_ErrorCellLowTemp:0, BMS_ErrorCellOverVolt:0, BMS_ErrorCellUnderVolt:0, BMS_ErrorChaCurrentOver:0, BMS_ErrorHighSoc:0, BMS_ErrorLowSoc:0, BMS_ErrorPreChaFailed:0, BMS_ErrorRelay:0, BMS_ThermalRunawayFault:0]}, required-interface=SG_BMS_ErrorInfo_SigGroup
      SG_CGW_VIN2_SigGroup: nonqueued-receiver-com-spec{data-element=SG_CGW_VIN2_SigGroup, enable-update=true, init-value=fields=[CGW_VIN8:0, CGW_VIN9:0, CGW_VIN10:0, CGW_VIN11:0, CGW_VIN12:0, CGW_VIN13:0, CGW_VIN14:0, CGW_VIN15:0]}, required-interface=SG_CGW_VIN2_SigGroup
      SG_BMS_status_02_SigGroup: nonqueued-receiver-com-spec{data-element=SG_BMS_status_02_SigGroup, enable-update=true, init-value=fields=[BMS_BattCurr:0, BMS_BattVolt:0, BMS_Heatcurrent:0]}, required-interface=SG_BMS_status_02_SigGroup
      SG_IBS_Status_05_SigGroup: nonqueued-receiver-com-spec{data-element=SG_IBS_Status_05_SigGroup, uses-end-to-end-protection=true, enable-update=true, filter=data-filter-type=ALWAYS, init-value=fields=[Checksum_0BB:0, IBS_SUBEPBworkingSts:0, MessageCounter_0BB:0, IBS_SUBEPBControllerSts:0, IBS_SUBEPBFailureStatus:0]}, required-interface=SG_IBS_Status_05_SigGroup_1
      SG_BMS_CellTemp_SigGroup: nonqueued-receiver-com-spec{data-element=SG_BMS_CellTemp_SigGroup, enable-update=true, filter=data-filter-type=ALWAYS, init-value=fields=[BMS_AverageCellTemp:215, BMS_MaxCellTemp:215, BMS_MaxCellTempNO:0, BMS_MinCellTemp:215, BMS_MinCellTempNO:0, BMS_MinCellTempModuleNO:0]}, required-interface=SG_BMS_CellTemp_SigGroup_1
      SG_IBS_Status_04_SigGroup: nonqueued-receiver-com-spec{data-element=SG_IBS_Status_04_SigGroup, uses-end-to-end-protection=true, enable-update=true, filter=data-filter-type=ALWAYS, init-value=fields=[Checksum_0BA:0, IBS_CDPActive:0, IBS_DTCActive:0, MessageCounter_0BA:0, IBS_CDPAvailable:0]}, required-interface=SG_IBS_Status_04_SigGroup_1
      SG_SGW_17_SigGroup: nonqueued-receiver-com-spec{data-element=SG_SGW_17_SigGroup, enable-update=true, init-value=fields=SGW_BLESystemReadyReq:0}, required-interface=SG_SGW_17_SigGroup
      SG_BMS_status_04_SigGroup: nonqueued-receiver-com-spec{data-element=SG_BMS_status_04_SigGroup, enable-update=true, filter=data-filter-type=ALWAYS, init-value=fields=[BMS_DisChgCurr:-1000, BMS_FeedbackCurr:-1000]}, required-interface=SG_BMS_status_04_SigGroup_2
      SG_BMS_PRO_SigGroup: nonqueued-receiver-com-spec{data-element=SG_BMS_PRO_SigGroup, enable-update=true, init-value=fields=[BMS_BatProDatDay:0, BMS_BatProDatMonth:0, BMS_BatProDatYear:0]}, required-interface=SG_BMS_PRO_SigGroup
      SG_ACU_01_SigGroup: nonqueued-receiver-com-spec{data-element=SG_ACU_01_SigGroup, uses-end-to-end-protection=true, enable-update=true, filter=data-filter-type=ALWAYS, init-value=fields=[ACU_YawRate:30000, ACU_YawRateStatus:0, Checksum_0F5:0, MessageCounter_0F5:0]}, required-interface=SG_ACU_01_SigGroup
      SG_ADCU_DA_SigGroup: nonqueued-receiver-com-spec{data-element=SG_ADCU_DA_SigGroup, uses-end-to-end-protection=true, enable-update=true, filter=data-filter-type=ALWAYS, init-value=fields=[ADCU_DA_Mode:0, Checksum_0E6:0, MessageCounter_0E6:0]}, required-interface=SG_ADCU_DA_SigGroup
      SG_POD_Status_02_SigGroup: nonqueued-receiver-com-spec{data-element=SG_POD_Status_02_SigGroup, enable-update=true, init-value=fields=[POD_DCPortInletTempAValid:0, POD_DCPortInletTempBValid:0, POD_DCPosRelayState:1]}, required-interface=SG_POD_Status_02_SigGroup
      SG_CGW_VIN1_SigGroup: nonqueued-receiver-com-spec{data-element=SG_CGW_VIN1_SigGroup, enable-update=true, init-value=fields=[CGW_VIN0:0, CGW_VIN1:0, CGW_VIN2:0, CGW_VIN3:0, CGW_VIN4:0, CGW_VIN5:0, CGW_VIN6:0, CGW_VIN7:0]}, required-interface=SG_CGW_VIN1_SigGroup
      SG_IVI_01_SigGroup: nonqueued-receiver-com-spec{data-element=SG_IVI_01_SigGroup, uses-end-to-end-protection=true, enable-update=true, filter=data-filter-type=ALWAYS, init-value=fields=IVI_GearRequest:0}, required-interface=SG_IVI_01_SigGroup
      SG_MCU_02_SigGroup: nonqueued-receiver-com-spec{data-element=SG_MCU_02_SigGroup, enable-update=true, init-value=fields=[MCU_BDmpCActv:0, MCU_VCUWorkMode:0]}, required-interface=SG_MCU_02_SigGroup
      SG_MCU_Temperature_02_SigGroup: nonqueued-receiver-com-spec{data-element=SG_MCU_Temperature_02_SigGroup, enable-update=true, init-value=fields=MCU_TempStatus:0}, required-interface=SG_MCU_Temperature_02_SigGroup
      SG_IBS_Status_03_SigGroup: nonqueued-receiver-com-spec{data-element=SG_IBS_Status_03_SigGroup, uses-end-to-end-protection=true, enable-update=true, filter=data-filter-type=ALWAYS, init-value=fields=[Checksum_0B4:0, IBS_ABPActive:0, IBS_ABSActive:0, IBS_EBDActive:0, IBS_EBDFault:0, IBS_SystemStatus:0, IBS_TCSFault:0, IBS_VCU_DecelerationRequest_Available:0, IBS_VehicleSpeed:0, MessageCounter_0B4:0, IBS_DTCFault:0, IBS_VehicleSpeedValid:0, IBS_ABPAvailable:0, IBS_ABSFault:0, IBS_EPBTextdisplay:0, IBS_VDCFault:0]}, required-interface=SG_IBS_Status_03_SigGroup_1
      SG_BMS_Charge_01_SigGroup: nonqueued-receiver-com-spec{data-element=SG_BMS_Charge_01_SigGroup, enable-update=true, init-value=fields=[BMS_AllowChagCurrent:0, BMS_MaxChagVoltage:0, BMS_RemChagTime:0]}, required-interface=SG_BMS_Charge_01_SigGroup
      SG_CGW_02_SigGroup: nonqueued-receiver-com-spec{data-element=SG_CGW_02_SigGroup, enable-update=true, init-value=fields=[CGW_ADCUSts:0, CGW_BCMSts:0, CGW_BMSSts:0, CGW_CBMSts:0, CGW_CGWSts:0, CGW_DCM_FLSts:0, CGW_DCM_FRSts:0, CGW_DCM_RLSts:0, CGW_DCM_RRSts:0, CGW_HLLSts:0, CGW_HLRSts:0, CGW_HOD_HeatingSts:0, CGW_IVISts:0, CGW_MFP_FCSts:0, CGW_MFP_RCSts:0, CGW_PRNDSts:0, CGW_SCU_LSts:0, CGW_SCU_RSts:0, CGW_SGWSts:0, CGW_SwichesSts:0, CGW_SWPSts:0, CGW_VCUSts:0]}, required-interface=SG_CGW_02_SigGroup
      SG_POD_OBC_STATUS_02_SigGroup: nonqueued-receiver-com-spec{data-element=SG_POD_OBC_STATUS_02_SigGroup, enable-update=true, init-value=fields=[POD_OBC_ChrgOutpPwrAvl:0, POD_OBC_OutputDCChargeCurrent:0, POD_OBC_OutputDCChargeVoltage:0]}, required-interface=SG_POD_OBC_STATUS_02_SigGroup
      SG_BMS_TCU_SigGroup: nonqueued-receiver-com-spec{data-element=SG_BMS_TCU_SigGroup, enable-update=true, init-value=fields=[BMS_AllowCellTemperature:255, BMS_KeepWarmRequest:0, BMS_KeepWarmStatus:0, BMS_RTC_Request:0]}, required-interface=SG_BMS_TCU_SigGroup
      SG_ACU_info_SigGroup: nonqueued-receiver-com-spec{data-element=SG_ACU_info_SigGroup, uses-end-to-end-protection=true, enable-update=true, filter=data-filter-type=ALWAYS, init-value=fields=[ACU_CrashOutputSts:1, ACU_CrashOutputStsValid:1, ACU_DriverWarningLampSts:0, ACU_PassengerAirbagSts:0, ACU_PassengerWarningLampSts:0, MessageCounter_097:0, Checksum_097:0, ACU_DriverSeatBeltSts:0, ACU_DriverSeatBeltStsValid:0, ACU_PassengerSeatBeltSts:0, ACU_PassengerSeatBeltStsValid:0, ACU_PassengerSts:0, ACU_RLSeatBeltStatusValid:0, ACU_RRSeatBeltStatusValid:0, ACU_SecondLeftSeatBeltSts:0, ACU_SecondLeftSts:0, ACU_SecondRightSeatBeltSts:0, ACU_SecondRightSts:0, ACU_WarningLampSts:0]}, required-interface=SG_ACU_info_SigGroup_1
      SG_ADCU_APS_02_SigGroup: nonqueued-receiver-com-spec{data-element=SG_ADCU_APS_02_SigGroup, enable-update=true, init-value=fields=ADCU_RemoteParkingMode:0}, required-interface=SG_ADCU_APS_02_SigGroup
      SG_MCU_FailureCode_SigGroup: nonqueued-receiver-com-spec{data-element=SG_MCU_FailureCode_SigGroup, uses-end-to-end-protection=true, enable-update=true, filter=data-filter-type=ALWAYS, init-value=fields=[Checksum_253:0, MCU_FaultLevel:0, MessageCounter_253:0]}, required-interface=SG_MCU_FailureCode_SigGroup
      SG_IVI_OdometerInfor_SigGroup: nonqueued-receiver-com-spec{data-element=SG_IVI_OdometerInfor_SigGroup, enable-update=true, init-value=fields=IVI_OdometerInfor:0}, required-interface=SG_IVI_OdometerInfor_SigGroup
      SG_DCM_RL_SigGroup: nonqueued-receiver-com-spec{data-element=SG_DCM_RL_SigGroup, enable-update=true, init-value=fields=DCM_RL_DoorRLSts:0}, required-interface=SG_DCM_RL_SigGroup
      SG_ADCU_APS_01_SigGroup: nonqueued-receiver-com-spec{data-element=SG_ADCU_APS_01_SigGroup, uses-end-to-end-protection=true, enable-update=true, filter=data-filter-type=ALWAYS, init-value=fields=[Checksum_0E4:0, MessageCounter_0E4:0, ADCU_Parking_Mode:0, ADCU_APS_Stop_Req:0, ADCU_APSComfBrkReq:0, ADCU_APSCrlModeReq:0, ADCU_APSCrlReq:0, ADCU_APSCrlTypReq:0, ADCU_APSDistanceStop:0, ADCU_APSMaxSpeedReq:0, ADCU_Parking_CtrlSts:0, ADCU_TargetGear:0]}, required-interface=SG_ADCU_APS_01_SigGroup_1
      SG_MCU_Temperature_01_SigGroup: nonqueued-receiver-com-spec{data-element=SG_MCU_Temperature_01_SigGroup, enable-update=true, init-value=fields=MCU_IGBTTempMax:0}, required-interface=SG_MCU_Temperature_01_SigGroup
      SG_POD_DCDC_01_SigGroup: nonqueued-receiver-com-spec{data-element=SG_POD_DCDC_01_SigGroup, enable-update=true, init-value=fields=[POD_DCDC_HVInputCurrent:0, POD_DCDC_HVInputVoltage:0, POD_DCDC_WorkMode:0]}, required-interface=SG_POD_DCDC_01_SigGroup
      SG_IBS_Status_02_SigGroup: nonqueued-receiver-com-spec{data-element=SG_IBS_Status_02_SigGroup, uses-end-to-end-protection=true, enable-update=true, filter=data-filter-type=ALWAYS, init-value=fields=[Checksum_0B3:0, IBS_AEBActive:0, IBS_EPBFailureLamp:0, IBS_EPBFunctionLamp:0, IBS_EPBworkingSts:0, IBS_TCSActive:0, IBS_VDCActive:0, MessageCounter_0B3:0, IBS_EPBControllerSts:0, IBS_AEBAvailable:0, IBS_AVHAvailable:0, IBS_AWBActive:0, IBS_AWBAvailable:0, IBS_BrakeLightRequest:0, IBS_HazWarnReq:0, IBS_HDCAvailable:0, IBS_HHCActive:0, IBS_HHCAvailable:0]}, required-interface=SG_IBS_Status_02_SigGroup_1
      SG_BCM_05_SigGroup: nonqueued-receiver-com-spec{data-element=SG_BCM_05_SigGroup, uses-end-to-end-protection=true, enable-update=true, filter=data-filter-type=ALWAYS, init-value=fields=[BCM_FLSeatBeltRemindReq:0, BCM_FRSeatBeltRemindReq:0, BCM_RLSeatBeltRemindReq:0, BCM_RRSeatBeltRemindReq:0, Checksum_33A:0, MessageCounter_33A:0, BCM_AutoCloseWinFunSts:0, BCM_ChrgFlapLockSts:0, BCM_DomeLampAutoSts:1, BCM_DomeLampBrightSts:1, BCM_FrontWiperModeSts:0, BCM_GearTimesSts:5, BCM_KeyNotInCarRemind:0, BCM_PuddleLiReq:1, BCM_WelLightshowOnOffSts:2, BCM_WiperServiceSts:0, BCM_WiperWorkingSts:0]}, required-interface=SG_BCM_05_SigGroup_1
      SG_IBS_APS_SigGroup: nonqueued-receiver-com-spec{data-element=SG_IBS_APS_SigGroup, uses-end-to-end-protection=true, enable-update=true, filter=data-filter-type=ALWAYS, init-value=fields=[IBS_APSTrqReqActive:0, Checksum_0B7:0, MessageCounter_0B7:0, IBS_APS_Avl:0, IBS_APSComfortAvl:0, IBS_APSCrlReqEcho:0, IBS_APSEmergenyAvl:0, IBS_APSModeEcho:0, IBS_BrakeTypEcho:0]}, required-interface=SG_IBS_APS_SigGroup_1
      SG_SGW_FVSynchronization_01_SigGrou: nonqueued-receiver-com-spec{data-element=SG_SGW_FVSynchronization_01_SigGrou, filter=data-filter-type=ALWAYS, init-value=fields=SGW_TripCounter:0}, required-interface=SG_SGW_FVSynchronization_01_SigGrou_1
      SG_BMS_BatInfor_02_SigGroup: nonqueued-receiver-com-spec{data-element=SG_BMS_BatInfor_02_SigGroup, enable-update=true, init-value=fields=BMS_BatSupName:0}, required-interface=SG_BMS_BatInfor_02_SigGroup
      SG_BCM_06_SigGroup: nonqueued-receiver-com-spec{data-element=SG_BCM_06_SigGroup, uses-end-to-end-protection=true, enable-update=true, filter=data-filter-type=ALWAYS, init-value=fields=[BCM_PepsPowerMode:0, checksum_271:0, MessageCounter_271:0, BCM_PowerOffDisplayReq:0]}, required-interface=SG_BCM_06_SigGroup_1
      SG_IBS_Status_01_SigGroup: nonqueued-receiver-com-spec{data-element=SG_IBS_Status_01_SigGroup, uses-end-to-end-protection=true, enable-update=true, filter=data-filter-type=ALWAYS, init-value=fields=[Checksum_0B2:0, IBS_PlungerPressure:-5, MessageCounter_0B2:0, IBS_BrakePedalStatus:0, IBS_BrakePedalStatusValid:1, IBS_BrakePushrodStroke:-5, IBS_MasterCylinderPressure:0]}, required-interface=SG_IBS_Status_01_SigGroup_2
      SG_IBS_Status_06_SigGroup: nonqueued-receiver-com-spec{data-element=SG_IBS_Status_06_SigGroup, uses-end-to-end-protection=true, enable-update=true, filter=data-filter-type=ALWAYS, init-value=fields=[Checksum_0BC:0, IBS_AVHSts:0, IBS_BrakeFluidWarning:0, IBS_ESCOffSts:1, IBS_HDCSts:0, IBS_RollerbenchMode:0, IBS_RWUActive:0, MessageCounter_0BC:0, IBS_EPBFailureStatus:0, IBS_ESClampdisplay:0, IBS_FactoryMode:0, IBS_HBAActive:0, IBS_MaintenaceMode:0, IBS_RWUAvailable:0, IBS_TireMonSysSts:1, IBS_TireWarnFrntLe:0, IBS_TireWarnFrntRi:0, IBS_TireWarnReLe:0, IBS_TireWarnReRi:0, IBS_TPMS_ResetSts:0]}, required-interface=SG_IBS_Status_06_SigGroup_1
      SG_BMS_status_03_SigGroup: nonqueued-receiver-com-spec{data-element=SG_BMS_status_03_SigGroup, enable-update=true, init-value=fields=[BMS_DisplaySOC:0, BMS_LinkVoltage:0, BMS_PackVoltage:0]}, required-interface=SG_BMS_status_03_SigGroup
      SG_DCM_FR_02_SigGroup: nonqueued-receiver-com-spec{data-element=SG_DCM_FR_02_SigGroup, enable-update=true, init-value=fields=[DCM_FR_AmbientTemperature:70, DCM_FR_AmbientTemperatureValid:0]}, required-interface=SG_DCM_FR_02_SigGroup
      SG_SGW_01_SigGroup: nonqueued-receiver-com-spec{data-element=SG_SGW_01_SigGroup, enable-update=true, filter=data-filter-type=ALWAYS, init-value=fields=[SGW_AppointChargeCmd:0, SGW_ChargeFormSet:0, SGW_LockACPlug:0, SGW_TimingChargeSwitchStatus:0, SGW_DschrgOnOffSet:0]}, required-interface=SG_SGW_01_SigGroup_1
      SG_IBS_Torque_SigGroup: nonqueued-receiver-com-spec{data-element=SG_IBS_Torque_SigGroup, uses-end-to-end-protection=true, enable-update=true, filter=data-filter-type=ALWAYS, init-value=fields=[Checksum_0B9:0, IBS_RBSStatus:0, IBS_TargetGearReq:0, IBS_WLTorqueAPSReq:0, IBS_WLTorqueAPSReqValid:0, IBS_WLTorqueRBSReq:0, IBS_WLTorqueRBSReqValid:0, MessageCounter_0B9:0, IBS_VCU_DecelerationReqActive:0]}, required-interface=SG_IBS_Torque_SigGroup
      SG_DCM_FL_02_SigGroup: nonqueued-receiver-com-spec{data-element=SG_DCM_FL_02_SigGroup, uses-end-to-end-protection=true, enable-update=true, filter=data-filter-type=ALWAYS, init-value=fields=[Checksum_28A:0, DCM_FL_DoorFLSts:0, MessageCounter_28A:0, DCM_FL_FRWndSwA:0, DCM_FL_LeftMirrorHorizontalPos:254, DCM_FL_LeftMirrorVerticalPos:254, DCM_FL_MirrorAutoFoldUnfoldSts:0, DCM_FL_MirrorAutoTurnDownSts:0, DCM_FL_MirrorFold_UnfoldSts:0, DCM_FL_RearmirrorHeatingSts:0, DCM_FL_RLWndSwA:0, DCM_FL_RRWndSwA:0]}, required-interface=SG_DCM_FL_02_SigGroup_1
      SG_IBS_ACC_SigGroup: nonqueued-receiver-com-spec{data-element=SG_IBS_ACC_SigGroup, uses-end-to-end-protection=true, enable-update=true, filter=data-filter-type=ALWAYS, init-value=fields=[Checksum_0B8:0, IBS_CddActive:0, IBS_VehicleStandstill:0, IBS_VehicleStandstill_Valid:0, IBS_VlcActive:0, IBS_WLTorqueVLCReq:-20000, IBS_WLTorqueVLCReqValid:0, MessageCounter_0B8:0, IBS_CddAvailable:0, IBS_CddError:0, IBS_VlcAvalible:0, IBS_VlcError:0]}, required-interface=SG_IBS_ACC_SigGroup_3
      SG_POD_OBC_CHRGSTATION_SigGroup: nonqueued-receiver-com-spec{data-element=SG_POD_OBC_CHRGSTATION_SigGroup, enable-update=true, init-value=fields=[POD_OBC_CCCurrentLimit:0, POD_OBC_CCStatus:0, POD_OBC_ChargCapacibility:0, POD_OBC_CPCurrentLimit:0, POD_OBC_CPDuty:0, POD_OBC_CPStatus:0, POD_OBC_EMLockState:0, POD_OBC_OBCMaxPermOutpCrrt:0, POD_OBC_S2State:1, POD_OBC_WorkMode:0]}, required-interface=SG_POD_OBC_CHRGSTATION_SigGroup
      SG_POD_OBC_STATUS_03_SigGroup: nonqueued-receiver-com-spec{data-element=SG_POD_OBC_STATUS_03_SigGroup, enable-update=true, init-value=fields=[POD_OBC_FaultLevel:0, POD_OBC_Side1Overtempfault:0, POD_OBC_Side2Overtempfault:0, POD_OBC_PrimarySideTemp:0, POD_OBC_SecondarySideTemp:0]}, required-interface=SG_POD_OBC_STATUS_03_SigGroup
      SG_POD_OBC_STATUS_04_SigGroup: nonqueued-receiver-com-spec{data-element=SG_POD_OBC_STATUS_04_SigGroup, enable-update=true, init-value=fields=[POD_OBC_InputACCurrent_R:0, POD_OBC_InputACCurrent_S:0, POD_OBC_InputACCurrent_T:0, POD_OBC_InputACVoltage_R:0, POD_OBC_InputACVoltage_S:0, POD_OBC_InputACVoltage_T:0]}, required-interface=SG_POD_OBC_STATUS_04_SigGroup
      SG_ACU_02_SigGroup: nonqueued-receiver-com-spec{data-element=SG_ACU_02_SigGroup, uses-end-to-end-protection=true, enable-update=true, filter=data-filter-type=ALWAYS, init-value=fields=[ACU_LatA:4905, ACU_LatAStatus:0, ACU_LgtA:4905, ACU_LgtAStatus:0, Checksum_0F6:0, MessageCounter_0F6:0]}, required-interface=SG_ACU_02_SigGroup
      SG_POD_Status_01_SigGroup: nonqueued-receiver-com-spec{data-element=SG_POD_Status_01_SigGroup, enable-update=true, init-value=fields=[POD_DCFCVoltage:0, POD_DCInletTempA:0, POD_DCInletTempB:0]}, required-interface=SG_POD_Status_01_SigGroup
      SG_BMS_VersionInfor_SigGroup: nonqueued-receiver-com-spec{data-element=SG_BMS_VersionInfor_SigGroup, enable-update=true, init-value=fields=[BMS_BatProRights:0, BMS_ComVersion:0]}, required-interface=SG_BMS_VersionInfor_SigGroup
      SG_BMS_BatInfor_01_SigGroup: nonqueued-receiver-com-spec{data-element=SG_BMS_BatInfor_01_SigGroup, enable-update=true, init-value=fields=[BMS_BatType:0, BMS_CellNumbers:0, BMS_RatBatVoltage:0, BMS_RatCapacity:0, BMS_RatEnergy:0]}, required-interface=SG_BMS_BatInfor_01_SigGroup
      SG_BMS_status_01_SigGroup: nonqueued-receiver-com-spec{data-element=SG_BMS_status_01_SigGroup, uses-end-to-end-protection=true, enable-update=true, filter=data-filter-type=ALWAYS, init-value=fields=[BMS_ChargeStatus:0, BMS_ErrorIsolationSingleLow:0, BMS_ErrorLevel:0, BMS_HVinterlockState:0, BMS_InsulationDetectionStatus:0, BMS_PreCharge:0, BMS_SOH:0, BMS_SysRegInsulationValue:0, BMS_ThrmlRunawayFault:0, BMS_WorkMode:0, Checksum_0C1:0, MessageCounter_0C1:0, BMS_BalancingStatus:0, BMS_RunHeatStatus:0]}, required-interface=SG_BMS_status_01_SigGroup_1
      SG_MCU_DeratingStatus_SigGroup: nonqueued-receiver-com-spec{data-element=SG_MCU_DeratingStatus_SigGroup, enable-update=true, init-value=fields=[MCU_TrqAbsMax:1023, MCU_TrqAbsMin:1023]}, required-interface=SG_MCU_DeratingStatus_SigGroup
      SG_SGW_VCU_01_SigGroup: nonqueued-receiver-com-spec{data-element=SG_SGW_VCU_01_SigGroup, enable-update=true, init-value=fields=[IVI_DriveModeSet:0, IVI_DschrgOnOffSet:0, IVI_ForwardVmaxAllowed:0, IVI_MaxChrgSocSet:254, IVI_V2LidisSet:254]}, required-interface=SG_SGW_VCU_01_SigGroup
      SG_SGW_IBS_01_SigGroup: nonqueued-receiver-com-spec{data-element=SG_SGW_IBS_01_SigGroup, uses-end-to-end-protection=true, enable-update=true, filter=data-filter-type=ALWAYS, init-value=fields=[IVI_BrakeCompensateCmd:0, IVI_CRLevelSet:0]}, required-interface=SG_SGW_IBS_01_SigGroup
      SG_DCM_RR_SigGroup: nonqueued-receiver-com-spec{data-element=SG_DCM_RR_SigGroup, uses-end-to-end-protection=true, enable-update=true, filter=data-filter-type=ALWAYS, init-value=fields=DCM_RR_DoorRRSts:0}, required-interface=SG_DCM_RR_SigGroup
      SG_BMS_DIRelayState_SigGroup: nonqueued-receiver-com-spec{data-element=SG_BMS_DIRelayState_SigGroup, enable-update=true, init-value=fields=[BMS_NegRelayStatus:0, BMS_PosRelayStatus:0, BMS_PreRelayStatus:0, BMS_PTC_VoltageValue:0, BMS_PTCRelayStatus:0]}, required-interface=SG_BMS_DIRelayState_SigGroup
      SG_TCU_02_SigGroup: nonqueued-receiver-com-spec{data-element=SG_TCU_02_SigGroup, enable-update=true, init-value=fields=[TCU_HVCHHighVoltage:0, TCU_HVCHHVDCCurrent:0]}, required-interface=SG_TCU_02_SigGroup
      SG_SGW_16_SigGroup: nonqueued-receiver-com-spec{data-element=SG_SGW_16_SigGroup, enable-update=true, init-value=fields=IVI_VrState:0}, required-interface=SG_SGW_16_SigGroup
      SG_APTC_TCU_SigGroup: nonqueued-receiver-com-spec{data-element=SG_APTC_TCU_SigGroup, enable-update=true, init-value=fields=APTC_PowerConsumption:0}, required-interface=SG_APTC_TCU_SigGroup
      SG_ADCU_ACC_02_SigGroup: nonqueued-receiver-com-spec{data-element=SG_ADCU_ACC_02_SigGroup, uses-end-to-end-protection=true, enable-update=true, filter=data-filter-type=ALWAYS, init-value=fields=[ADCU_ACC_Mode:0, Checksum_0E0:0, MessageCounter_0E0:0, ADCU_ACCDA_HandsOFF_Warning:0, ADCU_ACCDA_SYS_Failure:0]}, required-interface=SG_ADCU_ACC_02_SigGroup_1
      SG_TCU_01_SigGroup: nonqueued-receiver-com-spec{data-element=SG_TCU_01_SigGroup, enable-update=true, init-value=fields=[TCU_HVPwrState:0, TCU_TMSFaultLevel:0, TCU_TMSTotalPwrCnsmp:0, TCU_TMSTotoalPwrReq:0]}, required-interface=SG_TCU_01_SigGroup
      SG_ADCU_AEB_01_SigGroup: nonqueued-receiver-com-spec{data-element=SG_ADCU_AEB_01_SigGroup, uses-end-to-end-protection=true, enable-update=true, filter=data-filter-type=ALWAYS, init-value=fields=[ADCU_AEB_State:0, Checksum_0E2:0, MessageCounter_0E2:0, ADCU_AEB_AWB_Level:0, ADCU_AEB_AWB_Req:0, ADCU_AEB_Decel_Cmd:-16, ADCU_AEB_Prefill_CMD:0, ADCU_AEB_Stop_Req:0, ADCU_AEBReq:0, ADCU_AEBWarningSts:0, ADCU_FCW_State:0]}, required-interface=SG_ADCU_AEB_01_SigGroup_2
      SG_BMS_BatInfor_03_SigGroup: nonqueued-receiver-com-spec{data-element=SG_BMS_BatInfor_03_SigGroup, enable-update=true, init-value=fields=BMS_RemainCapacity:0}, required-interface=SG_BMS_BatInfor_03_SigGroup
      SG_BMS_Charge_03_SigGroup: nonqueued-receiver-com-spec{data-element=SG_BMS_Charge_03_SigGroup, enable-update=true, init-value=fields=[BMS_BatChagSum:0, BMS_SingChgkwh:0, BMS_SumChgkwh:0]}, required-interface=SG_BMS_Charge_03_SigGroup
      SG_BMS_Charge_02_SigGroup: nonqueued-receiver-com-spec{data-element=SG_BMS_Charge_02_SigGroup, enable-update=true, init-value=fields=[BMS_AbortAchivesetValue:0, BMS_AbortAchiveSingleVolt:0, BMS_AbortAchiveTotalVolt:0, BMS_AbortErrorCurrent:0, BMS_AbortErrorVoltage:0, BMS_AbortFaultBatteryTemp:0, BMS_AbortFaultBMSTemp:0, BMS_ChagComplete:0, BMS_ChargeRequest:0, BMS_DCChgMode:0]}, required-interface=SG_BMS_Charge_02_SigGroup
      SG_IBS_WheelSpeed_02_SigGroup: nonqueued-receiver-com-spec{data-element=SG_IBS_WheelSpeed_02_SigGroup, uses-end-to-end-protection=true, enable-update=true, filter=data-filter-type=ALWAYS, init-value=fields=[Checksum_0B1:0, IBS_RLMovingDirection:0, IBS_RLWheelSpeed:0, IBS_RLWheelSpeed_Fault:0, IBS_RRMovingDirection:0, IBS_RRWheelSpeed:0, IBS_RRWheelSpeed_Fault:0, MessageCounter_0B1:0, IBS_RLWheelPulseCounter:0, IBS_RRWheelPulseCounter:0]}, required-interface=SG_IBS_WheelSpeed_02_SigGroup_1
      SG_EVCOM_State_01_SigGroup: nonqueued-receiver-com-spec{data-element=SG_EVCOM_State_01_SigGroup, enable-update=true, init-value=fields=[EVCOM_CompActlCnsmpCur:0, EVCOM_CompActlPwrCnsmp:0]}, required-interface=SG_EVCOM_State_01_SigGroup
